VERSION "berumiya 990S labo"
CM_ "License: CC-BY 4.0";
CM_ "Repository : https://github.com/berumiya/CAN_DBC_6thGenMazda";
CM_ "Decoded and maintained by berumiya 990S labo";
CM_ "Source : reverse-engineered CAN traffic.";

NS_ :

BS_:
BU_: HS_SSU HS_CMU HS_BCMM HS_LVL HS_ABS HS_IC HS_RCM HS_EPAS HS_FSC2 HS_PCM HS_EVP HS_DCDC HS_MRCC HS_HUD_MZ HS_RHT HS_TCUAT OBD2 UNKNOWN_ECU
BO_ 145 HS_SSU: 8 HS_SSU
   SG_ MsgCounter_maybe : 31|8@0+ (1,0) [0|255] "" Vector__XXX
   SG_ HAZ_SW : 10|1@0+ (1,0) [0|1] "" Vector__XXX
   SG_ WIP_F_INT : 55|8@0+ (1,0) [0|1] "" Vector__XXX
   SG_ TURN_SW : 13|2@0+ (1,0) [0|1] "" Vector__XXX
   SG_ FOG_SW : 1|2@0+ (1,0) [0|1] "" Vector__XXX
   SG_ RearWiper : 19|2@0+ (1,0) [0|1] "" Vector__XXX
   SG_ Washer : 17|2@0+ (1,0) [0|1] "" Vector__XXX
   SG_ FrontWiper : 21|2@0+ (1,0) [0|1] "" Vector__XXX
   SG_ LIGHT : 7|6@0+ (1,0) [0|1] "" Vector__XXX

BO_ 70 HS_SSU: 8 HS_SSU

BO_ 80 HS_SSU: 8 HS_SSU
   SG_ iStop_EngineStopped_2 : 20|1@0+ (1,0) [0|1] "" Vector__XXX
   SG_ KeyState : 1|2@0+ (1,0) [0|1] "" Vector__XXX
   SG_ KeyStateInv : 58|3@0+ (1,0) [0|1] "" Vector__XXX
   SG_ StarterInterLockSW : 25|1@0+ (1,0) [0|1] "" Vector__XXX

BO_ 130 HS_SSU: 8 HS_SSU
   SG_ Steering_Wheel_Absolute_Angle : 23|16@0+ (0.05,-1600) [0|1] "deg" Vector__XXX
   SG_ SteeringRate_Abs_maybe : 44|12@1+ (0.5,0) [0|2047] "deg/s" Vector__XXX
   SG_ SteeringRate_Dir_maybe : 56|1@1+ (1,0) [0|1] "" Vector__XXX

BO_ 157 HS_SSU: 8 HS_SSU
   SG_ CRU_CON_SW1 : 7|10@0+ (1,0) [0|1] "" Vector__XXX
   SG_ CruiseMainSwitch_maybe : 13|1@0+ (1,0) [0|1] "" Vector__XXX

BO_ 628 HS_SSU: 8 HS_SSU
   SG_ INFO_SW : 61|2@0+ (1,0) [0|1] "" Vector__XXX
   SG_ Key_hold : 20|1@0+ (1,0) [0|1] "" Vector__XXX
   SG_ Key_notfound : 36|1@0+ (1,0) [0|1] "" Vector__XXX
   SG_ IC_Buzz : 7|8@0+ (1,0) [0|1] "" Vector__XXX
   SG_ Key_Batt : 39|1@0+ (1,0) [0|1] "" Vector__XXX
   SG_ Key_fob : 47|4@0+ (1,0) [0|1] "" Vector__XXX

BO_ 1154 HS_SSU: 8 HS_SSU

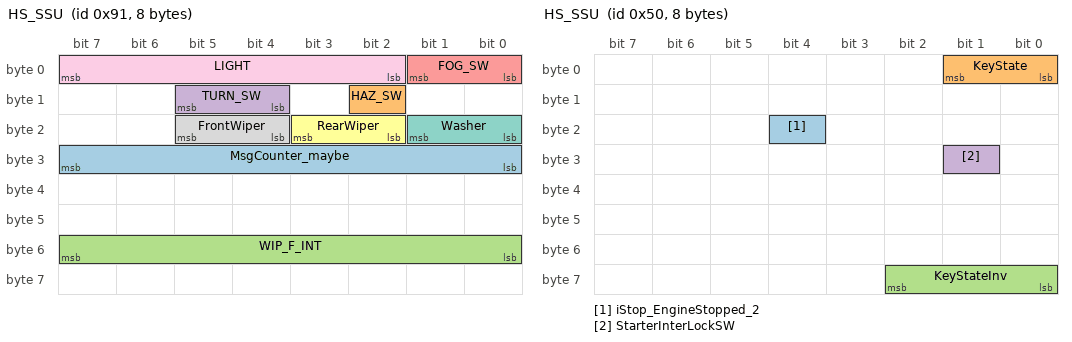
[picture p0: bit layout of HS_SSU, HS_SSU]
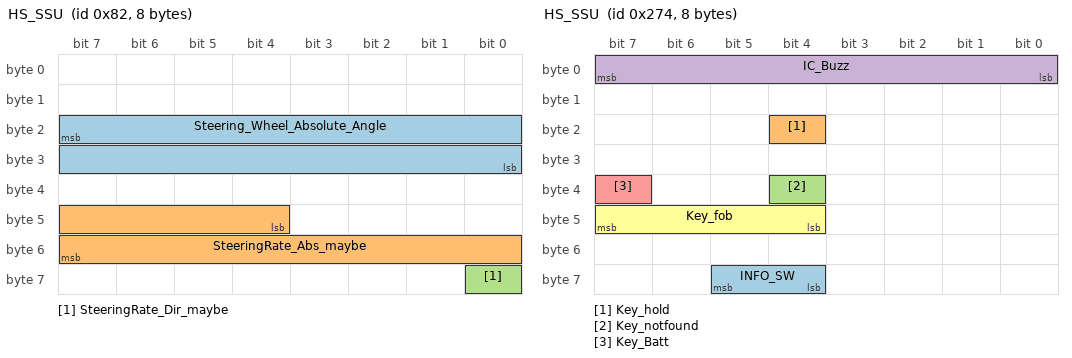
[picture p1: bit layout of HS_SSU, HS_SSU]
BO_ 1416 HS_SSU: 8 HS_SSU

BO_ 158 HS_IC: 8 HS_IC
   SG_ Fuel_Tank : 47|8@0+ (0.2,0) [0|1] "L" Vector__XXX
   SG_ Fuel_Related_2 : 55|8@0+ (1,0) [0|1] "" Vector__XXX
   SG_ DSC_OFF_Switch : 3|1@0+ (1,0) [0|1] "" Vector__XXX
   SG_ LDWS_ON_Switch : 8|1@0+ (1,0) [0|1] "" Vector__XXX
   SG_ BSM_RVM_ON_Switch : 9|1@0+ (1,0) [0|1] "" Vector__XXX
   SG_ iStop_OFF_Switch : 2|1@0+ (1,0) [0|1] "" Vector__XXX

BO_ 159 HS_IC: 8 HS_IC
   SG_ EngineRunning_2 : 16|1@0+ (1,0) [0|1] "" Vector__XXX
   SG_ PCONSW_Panel_Light_Control_Switch : 15|8@0+ (1,0) [0|1] "%" Vector__XXX
   SG_ DIM_CSW_Dimmer_Cancel_Switch : 47|1@0+ (1,0) [0|1] "" Vector__XXX
   SG_ Reverse_Flag_maybe : 7|1@0+ (1,0) [0|1] "" Vector__XXX
   SG_ ReverseGear_IC : 0|1@0+ (1,0) [0|1] "" Vector__XXX
   SG_ Parking_Brake : 4|1@0+ (1,0) [0|1] "" Vector__XXX

BO_ 606 HS_IC: 8 HS_IC
   SG_ VehicleSpeed : 7|10@0+ (1,0) [0|1] "" HS_HUD_MZ
   SG_ SpeedUnit : 13|1@0+ (1,0) [0|1] "" Vector__XXX
   SG_ StopVehicle : 28|1@0+ (1,0) [0|1] "" Vector__XXX
   SG_ DAA_Related : 63|4@0+ (1,0) [0|1] "" Vector__XXX

BO_ 607 HS_IC_PSM_MZ: 8 HS_IC

BO_ 1034 HS_IC_CentralConfig: 8 HS_IC
   SG_ C000_TOTAL_TIME m49152M : 23|32@0+ (0.1,1) [0|1] "sec" Vector__XXX
   SG_ C001_ODO m49153M : 23|32@0+ (1,0) [0|1] "km" Vector__XXX
   SG_ C100_VIN_1_6 m49408M : 23|48@0- (1,0) [0|1] "" Vector__XXX
   SG_ C101_VIN_7_12 m49409M : 23|48@0- (1,0) [0|1] "" Vector__XXX
   SG_ C102_VIN_13_17 m49410M : 23|40@0- (1,0) [0|1] "" Vector__XXX
   SG_ C103 m49411M : 23|48@0+ (1,0) [0|1] "" Vector__XXX
   SG_ C104 m49412M : 23|48@0+ (1,0) [0|1] "" Vector__XXX
   SG_ BF00_IG_ON_Timer m48896M : 39|16@0+ (1,0) [0|1] "sec" Vector__XXX
   SG_ BF01 m48897M : 23|48@0+ (1,0) [0|1] "" Vector__XXX
   SG_ BF02 m48898M : 23|48@0+ (1,0) [0|1] "" Vector__XXX
   SG_ BF03 m48899M : 23|48@0+ (1,0) [0|1] "" Vector__XXX
   SG_ BF04 m48900M : 23|48@0+ (1,0) [0|1] "" Vector__XXX
   SG_ BF05 m48901M : 23|48@0+ (1,0) [0|1] "" Vector__XXX
   SG_ BF06 m48902M : 23|48@0+ (1,0) [0|1] "" Vector__XXX
   SG_ BF07 m48903M : 23|48@0+ (1,0) [0|1] "" Vector__XXX
   SG_ BF08 m48904M : 23|48@0+ (1,0) [0|1] "" Vector__XXX
   SG_ BF09 m48905M : 23|48@0+ (1,0) [0|1] "" Vector__XXX
   SG_ BF0A m48906M : 23|48@0+ (1,0) [0|1] "" Vector__XXX
   SG_ BF0B m48907M : 23|48@0+ (1,0) [0|1] "" Vector__XXX
   SG_ BF0C m48908M : 23|48@0+ (1,0) [0|1] "" Vector__XXX
   SG_ BF0D m48909M : 23|48@0+ (1,0) [0|1] "" Vector__XXX
   SG_ BF0E m48910M : 23|48@0+ (1,0) [0|1] "" Vector__XXX
   SG_ BF0F m48911M : 23|48@0+ (1,0) [0|1] "" Vector__XXX
   SG_ BF10 m48912M : 23|48@0+ (1,0) [0|1] "" Vector__XXX
   SG_ BF11 m48913M : 23|48@0+ (1,0) [0|1] "" Vector__XXX
   SG_ BF12 m48914M : 23|48@0+ (1,0) [0|1] "" Vector__XXX
   SG_ BF13 m48915M : 23|48@0+ (1,0) [0|1] "" Vector__XXX
   SG_ BF14 m48916M : 23|48@0+ (1,0) [0|1] "" Vector__XXX
   SG_ BF15 m48917M : 23|48@0+ (1,0) [0|1] "" Vector__XXX
   SG_ BF16 m48918M : 23|48@0+ (1,0) [0|1] "" Vector__XXX
   SG_ BF17 m48919M : 23|48@0+ (1,0) [0|1] "" Vector__XXX
   SG_ BF18 m48920M : 23|48@0+ (1,0) [0|1] "" Vector__XXX
   SG_ BF19 m48921M : 23|48@0+ (1,0) [0|1] "" Vector__XXX
   SG_ BF1A m48922M : 23|48@0+ (1,0) [0|1] "" Vector__XXX
   SG_ BF1B m48923M : 23|48@0+ (1,0) [0|1] "" Vector__XXX
   SG_ BF1C m48924M : 23|48@0+ (1,0) [0|1] "" Vector__XXX
   SG_ BF1D m48925M : 23|48@0+ (1,0) [0|1] "" Vector__XXX
   SG_ BF1E m48926M : 23|48@0+ (1,0) [0|1] "" Vector__XXX
   SG_ BF1F m48927M : 23|48@0+ (1,0) [0|1] "" Vector__XXX
   SG_ BF20 m48928M : 23|48@0+ (1,0) [0|1] "" Vector__XXX
   SG_ BF21 m48929M : 23|48@0+ (1,0) [0|1] "" Vector__XXX
   SG_ Central_Config_Index M : 7|16@0+ (1,0) [0|1] "" Vector__XXX

BO_ 1078 HS_IC_EATC: 8 HS_IC

BO_ 1093 HS_IC_PSM_MZ: 8 HS_IC
   SG_ ReverseGear : 7|1@0+ (1,0) [0|1] "" Vector__XXX
   SG_ PSM_State_maybe : 23|8@0+ (1,0) [0|255] "" Vector__XXX

BO_ 1143 HS_IC: 8 HS_IC
   SG_ GearDisplay_related_maybe : 15|8@0+ (1,0) [0|255] "" Vector__XXX

BO_ 1147 HS_IC: 8 HS_IC
   SG_ BSM_Warning : 2|1@0+ (1,0) [0|1] "" Vector__XXX
   SG_ BSM_Right : 1|1@0+ (1,0) [0|1] "" Vector__XXX
   SG_ BSM_Left : 15|1@0+ (1,0) [0|1] "" Vector__XXX
   SG_ BSM_Status : 4|1@0+ (1,0) [0|1] "" Vector__XXX

BO_ 1166 HS_IC_PSM_MZ: 8 HS_IC

BO_ 1170 HS_IC: 8 HS_IC

BO_ 1173 HS_IC: 8 HS_IC

BO_ 1180 HS_IC: 8 HS_IC
   SG_ RoadIncline_maybe : 63|7@0+ (1,-32) [-32|95] "%" Vector__XXX

BO_ 1267 HS_IC: 8 HS_IC
   SG_ AvgFuelConsumption : 39|16@0+ (0.01,0) [0|655.35] "l/100km" Vector__XXX

BO_ 1271 HS_IC: 8 HS_IC
   SG_ ColdEngine_Indicator : 5|2@0+ (1,0) [0|3] "" Vector__XXX

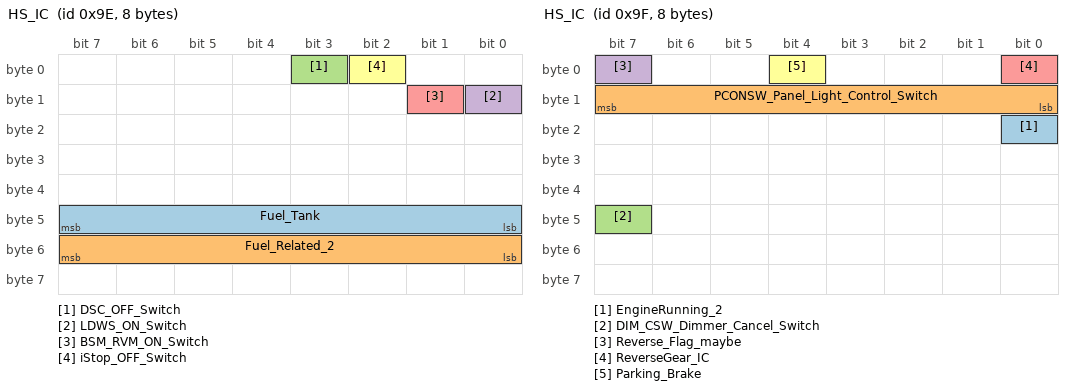
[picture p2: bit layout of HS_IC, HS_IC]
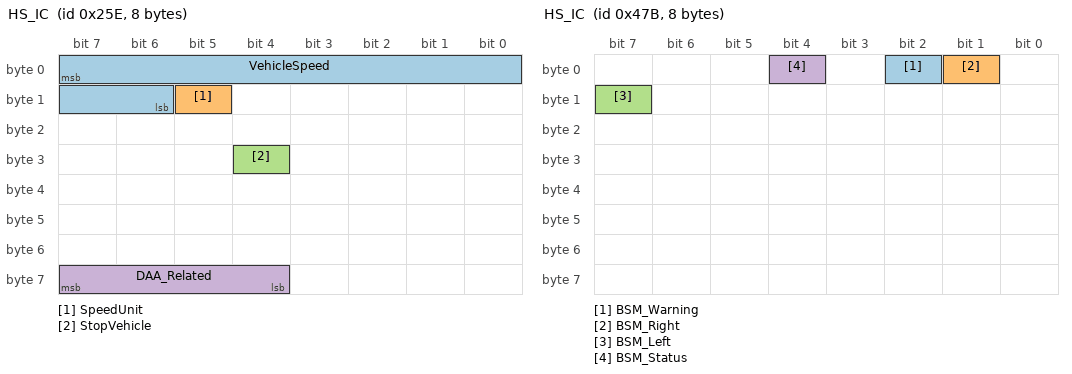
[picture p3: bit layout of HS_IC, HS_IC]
BO_ 1425 HS_IC: 8 HS_IC

BO_ 1776 HS_IC_NSWdiag: 8 HS_IC

BO_ 1778 HS_IC_NSWdiag: 8 HS_IC

BO_ 120 HS_ABS: 8 HS_ABS
   SG_ BrakePressure : 39|16@0- (0.0012709,33.5487) [0|45] "bar" Vector__XXX
   SG_ Longi_Acc_Corr : 7|16@0+ (0.000512295,-29.2787) [0|1] "G" Vector__XXX
   SG_ YawRate_related : 23|16@0- (0.0011,0) [-45|45] "deg/s" Vector__XXX

BO_ 121 HS_ABS: 8 HS_ABS
   SG_ MsgCounter_maybe : 55|8@0+ (1,0) [0|255] "" Vector__XXX
   SG_ Lateral_Acc_Corr_maybe : 7|16@0+ (0.000512295,-29.2787) [0|1] "" Vector__XXX
   SG_ YawRate_Corr : 31|16@0+ (0.133,-68.1) [-45|45] "deg/s" Vector__XXX

BO_ 529 HS_ABS: 8 HS_ABS
   SG_ ABS_Active : 42|1@0+ (1,0) [0|1] "" Vector__XXX
   SG_ TCS_Active_maybe : 40|1@0+ (1,0) [0|1] "" Vector__XXX
   SG_ HighDecel_maybe : 43|1@0+ (1,0) [0|1] "" Vector__XXX
   SG_ TCS_TorqueRequest_maybe : 23|16@0+ (1,-32768) [-32768|32767] "" Vector__XXX
   SG_ TCS_RequestActive_maybe : 53|1@0+ (1,0) [0|1] "" Vector__XXX

BO_ 533 HS_ABS: 8 HS_ABS
   SG_ WheelSpeed_1 : 7|16@0+ (0.01,-100) [0|1] "km/h" Vector__XXX
   SG_ WheelSpeed_2 : 23|16@0+ (0.01,-100) [0|1] "km/h" Vector__XXX
   SG_ WheelSpeed_3 : 39|16@0+ (0.01,-100) [0|1] "km/h" Vector__XXX
   SG_ WheelSpeed_4 : 55|16@0+ (0.01,-100) [0|1] "km/h" Vector__XXX

BO_ 535 HS_ABS: 8 HS_ABS
   SG_ VehicleSpeed_ABS_raw : 39|16@0+ (0.01,0) [0|655.35] "km/h" Vector__XXX

BO_ 542 HS_ABS: 8 HS_ABS
   SG_ MsgCounter_maybe : 55|8@0+ (1,0) [0|255] "" Vector__XXX

BO_ 736 HS_ABS: 8 HS_ABS

BO_ 1045 HS_ABS: 8 HS_ABS
   SG_ BrakeRelated_weak_maybe : 15|8@0+ (1,0) [0|255] "" Vector__XXX
   SG_ DSC_Status : 4|1@0+ (1,0) [0|1] "" Vector__XXX
   SG_ DSC_Indicator_maybe : 2|2@0+ (1,0) [0|3] "" Vector__XXX

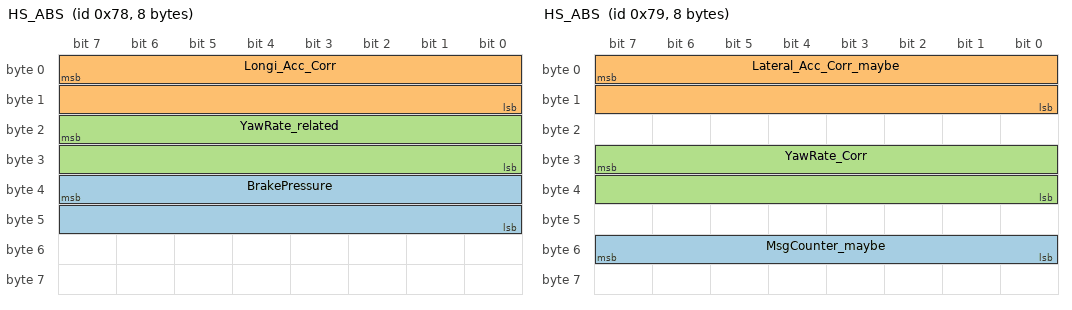
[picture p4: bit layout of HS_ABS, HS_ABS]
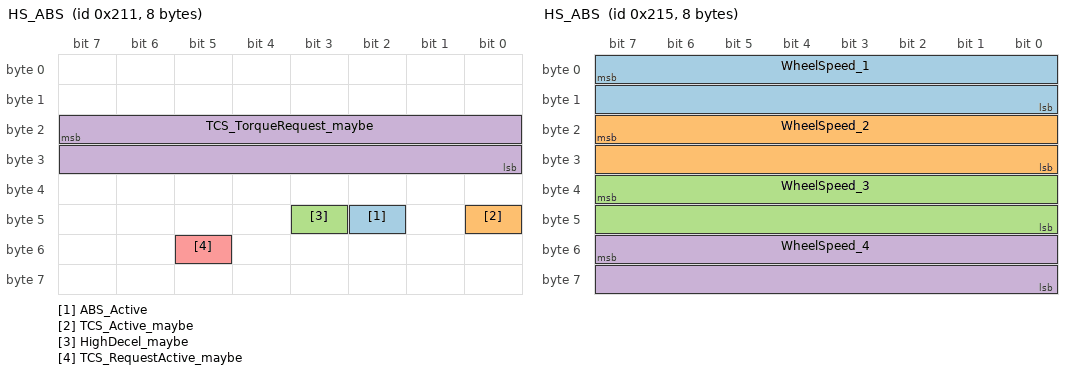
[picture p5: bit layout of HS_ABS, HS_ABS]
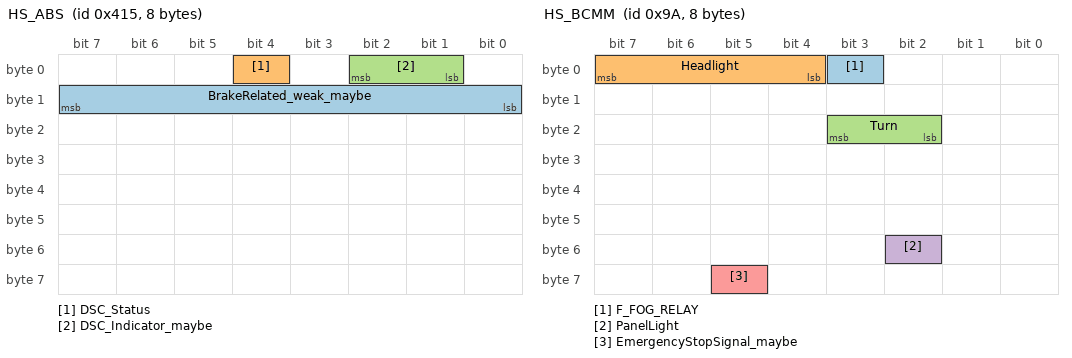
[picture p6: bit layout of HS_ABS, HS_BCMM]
BO_ 1430 HS_ABS: 8 HS_ABS

BO_ 154 HS_BCMM: 8 HS_BCMM
   SG_ F_FOG_RELAY : 3|1@0+ (1,0) [0|1] "" Vector__XXX
   SG_ Headlight : 7|4@0+ (1,0) [0|1] "" Vector__XXX
   SG_ Turn : 19|2@0+ (1,0) [0|1] "" Vector__XXX
   SG_ PanelLight : 50|1@0+ (1,0) [0|1] "" Vector__XXX
   SG_ EmergencyStopSignal_maybe : 61|1@0+ (1,0) [0|1] "" Vector__XXX

BO_ 155 HS_BCMM: 8 HS_BCMM

BO_ 1085 HS_BCMM: 8 HS_BCMM

BO_ 1086 HS_BCMM: 8 HS_BCMM
   SG_ ROOM_FUSE : 51|1@0+ (1,0) [0|1] "" Vector__XXX
   SG_ R_FOG_LAMP : 6|1@0+ (1,0) [0|1] "" Vector__XXX
   SG_ Trunk : 47|1@0+ (1,0) [0|1] "" Vector__XXX
   SG_ DoorRight : 37|1@0+ (1,0) [0|1] "" Vector__XXX
   SG_ DoorLeft : 36|1@0+ (1,0) [0|1] "" Vector__XXX
   SG_ AnyDoorOpen : 30|1@0+ (1,0) [0|1] "" Vector__XXX
   SG_ BrakeLamp : 53|1@0+ (1,0) [0|1] "" Vector__XXX

BO_ 1087 HS_BCMM: 8 HS_BCMM
   SG_ BCM_SupplyVoltage : 19|10@0+ (0.016,0) [0|16.37] "V" Vector__XXX
   SG_ Fuel_Related : 7|10@0+ (1,0) [0|1] "" Vector__XXX

BO_ 1114 HS_BCMM: 8 HS_BCMM
   SG_ BattSensor_Voltage_maybe : 45|13@0+ (0.002,-0.1) [0|16] "V" Vector__XXX
   SG_ BattSensor_Current_raw_maybe : 3|12@0+ (1,0) [0|4095] "" Vector__XXX
   SG_ BattSensor_Temp_maybe : 31|8@0+ (1,-40) [-40|215] "degC" Vector__XXX
   SG_ BattSensor_Byte4_maybe : 39|8@0+ (1,0) [0|255] "" Vector__XXX
   SG_ BattSensor_Byte7_maybe : 63|8@0+ (1,0) [0|255] "" Vector__XXX

BO_ 1115 HS_BCMM: 8 HS_BCMM

BO_ 1116 HS_BCMM: 8 HS_BCMM

BO_ 1163 HS_BCMM: 8 HS_BCMM

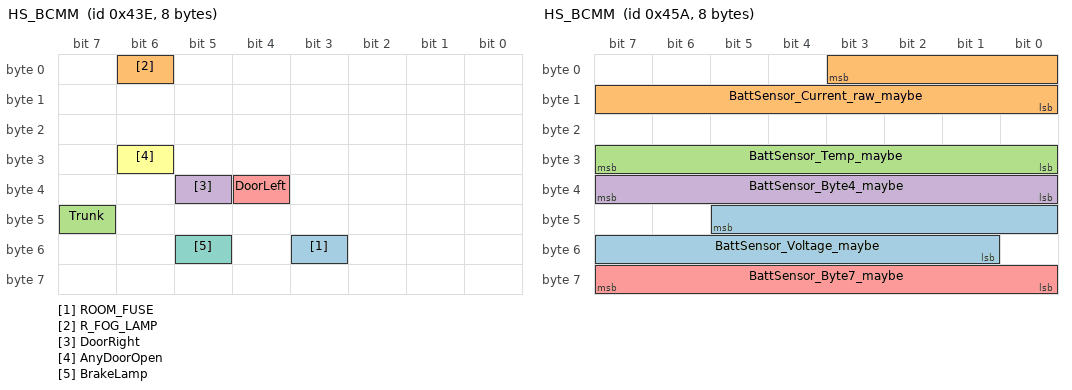
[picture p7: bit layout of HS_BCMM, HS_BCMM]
BO_ 1409 HS_BCMM: 8 HS_BCMM

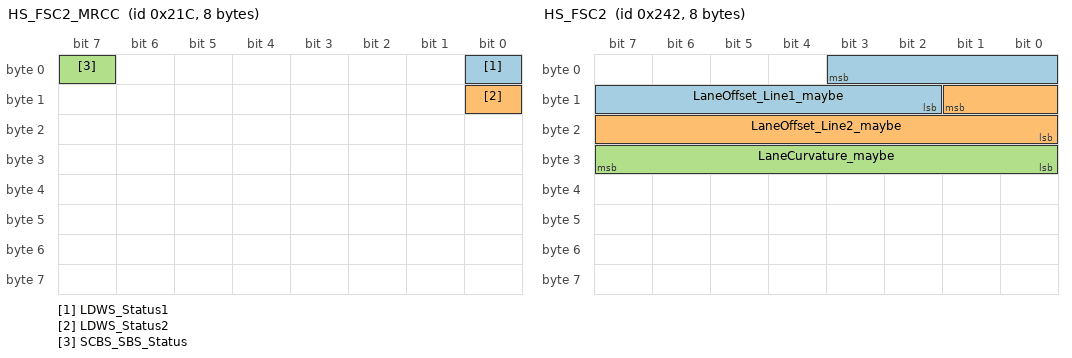
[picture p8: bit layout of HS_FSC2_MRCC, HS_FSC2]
BO_ 540 HS_FSC2_MRCC: 8 HS_FSC2
   SG_ LDWS_Status1 : 0|1@0+ (1,0) [0|1] "" Vector__XXX
   SG_ LDWS_Status2 : 8|1@0+ (1,0) [0|1] "" Vector__XXX
   SG_ SCBS_SBS_Status : 7|1@0+ (1,0) [0|1] "" Vector__XXX

BO_ 541 HS_FSC2: 8 HS_FSC2

BO_ 578 HS_FSC2: 8 HS_FSC2
   SG_ LaneOffset_Line1_maybe : 3|10@0+ (1,-686) [-686|337] "cm" Vector__XXX
   SG_ LaneOffset_Line2_maybe : 9|10@0+ (1,-686) [-686|337] "cm" Vector__XXX
   SG_ LaneCurvature_maybe : 31|8@0+ (0.3,-38.1) [-38.1|38.4] "1/km" Vector__XXX

BO_ 579 HS_FSC2: 8 HS_FSC2

BO_ 580 HS_FSC2: 8 HS_FSC2

BO_ 581 HS_FSC2: 8 HS_FSC2
   SG_ CAM581_Curvature2_raw_maybe : 39|8@0+ (1,0) [0|255] "" Vector__XXX
   SG_ CAM581_LineDiff_raw_maybe : 7|8@0+ (1,0) [0|255] "" Vector__XXX

BO_ 582 HS_FSC2: 8 HS_FSC2

BO_ 605 HS_FSC2: 8 HS_FSC2

BO_ 863 HS_FSC2: 8 HS_FSC2
   SG_ TSR_SpeedLimit : 4|7@0+ (1,0) [0|127] "km/h" Vector__XXX

BO_ 1088 HS_FSC2: 8 HS_FSC2

BO_ 1157 HS_FSC2: 8 HS_FSC2
   SG_ SCBS_SBS_Status : 28|2@0+ (1,0) [0|1] "" Vector__XXX

BO_ 1160 HS_FSC2: 8 HS_FSC2

BO_ 1061 HS_LVL: 8 HS_LVL

BO_ 64 HS_PCM: 8 HS_PCM

BO_ 253 HS_PCM: 8 HS_PCM
   SG_ EngineRunning_3 : 6|1@0+ (1,0) [0|1] "" Vector__XXX
   SG_ EngineRunning : 0|1@0+ (1,0) [0|1] "" Vector__XXX
   SG_ FuelCut : 41|1@0+ (1,0) [0|1] "" Vector__XXX
   SG_ MT_Gear_Recommend : 13|3@0+ (1,0) [0|1] "" Vector__XXX
   SG_ MT_Gear_Actual : 19|3@0+ (1,0) [0|1] "" Vector__XXX
   SG_ MAP_Manifold_absolute_pressure_sensor : 55|8@0+ (1,2) [10|115] "kPa" Vector__XXX
   SG_ CruiseActive_Inv : 61|1@0+ (1,0) [0|1] "" Vector__XXX

BO_ 254 HS_PCM: 8 HS_PCM
   SG_ MsgCounter_maybe : 55|8@0+ (1,0) [0|255] "" Vector__XXX
   SG_ SlowlyVarying_unclear : 63|8@0+ (1,0) [0|255] "" Vector__XXX

BO_ 357 HS_PCM: 8 HS_PCM
   SG_ Clutch_Related : 22|7@0+ (1,0) [0|1] "" Vector__XXX
   SG_ MT_Gear_Select : 36|2@0+ (1,0) [0|1] "" Vector__XXX
   SG_ CC_SetSpeed : 14|8@0+ (1,0) [0|1] "km/h" Vector__XXX
   SG_ CC_Mode_Related : 7|9@0+ (1,0) [0|1] "" Vector__XXX
   SG_ CC_Mode_Related2 : 31|8@0+ (1,0) [0|1] "" Vector__XXX
   SG_ MT_Gear_Position : 55|8@0+ (1,0) [0|255] "" Vector__XXX

BO_ 358 HS_PCM: 8 HS_PCM
   SG_ Clutch_Pedal_Position_related_2 : 7|8@0+ (1.25,0) [0|199] "" Vector__XXX
   SG_ BBP_Brake_Booster_Pressure_2 : 11|12@0+ (0.1,0) [0|1] "kPa" Vector__XXX
   SG_ BARO_Barometric_pressure : 35|12@0+ (0.1,-267) [0|1] "kPa" Vector__XXX

BO_ 304 HS_PCM: 8 HS_PCM
   SG_ iStop_Ready_maybe : 20|1@0+ (1,0) [0|1] "" Vector__XXX
   SG_ iStop_EngineStopped : 19|1@0+ (1,0) [0|1] "" Vector__XXX
   SG_ iStop_Stopping_B : 10|1@0+ (1,0) [0|1] "" Vector__XXX
   SG_ iStop_Stopping_A : 0|1@0+ (1,0) [0|1] "" Vector__XXX
   SG_ iStop_StopRequest : 30|1@0+ (1,0) [0|1] "" Vector__XXX
   SG_ EngineRPM_related_2 : 47|16@0+ (0.5,0) [0|8000] "rpm" Vector__XXX
   SG_ Clutch_Pedal_Position_raw : 63|8@0+ (1,0) [0|199] "" Vector__XXX

BO_ 359 HS_PCM: 8 HS_PCM
   SG_ iStop_StopRequest_PCM : 22|1@0+ (1,0) [0|1] "" Vector__XXX
   SG_ APP_Accelerator_Pedal_Position : 7|10@0+ (0.1,0) [0|1] "%" Vector__XXX
   SG_ ActualEnginePercentTorque : 39|8@0+ (3.1028,-183.019) [-183.019|608.195] "%" Vector__XXX
   SG_ BrakeSwitch_PCM : 19|1@0+ (1,0) [0|1] "" Vector__XXX
   SG_ BrakeSwitch_PCM_Inv : 18|1@0+ (1,0) [0|1] "" Vector__XXX
   SG_ BrakeSwitch_PCM_2 : 16|1@0+ (1,0) [0|1] "" Vector__XXX

BO_ 512 HS_PCM: 8 HS_PCM
   SG_ PCM_TorqueLoss_raw_maybe : 23|16@0+ (1,-32768) [-32768|32767] "" Vector__XXX
   SG_ EngineLoad_related_maybe : 7|16@0+ (1,0) [0|65535] "" Vector__XXX
   SG_ EngineTorque_related_maybe : 39|16@0+ (1,0) [0|65535] "" Vector__XXX

BO_ 514 HS_PCM: 8 HS_PCM
   SG_ EngineRPM : 7|16@0+ (0.25,0) [0|1] "rpm" Vector__XXX
   SG_ VehicleSpeed : 23|16@0+ (0.01,0) [0|1] "km/h" Vector__XXX
   SG_ APP_Accelerator_Pedal_Position : 39|16@0+ (0.0015625,0) [0|1] "%" Vector__XXX

BO_ 522 HS_PCM_w_i_ELOOP: 8 HS_PCM
   SG_ EngineState_raw_maybe : 7|6@0+ (1,0) [0|63] "" Vector__XXX
   SG_ PCM_20A_Ramp_raw_maybe : 1|8@0+ (1,0) [0|255] "" Vector__XXX
   SG_ FuelNotCut_maybe : 39|1@0+ (1,0) [0|1] "" Vector__XXX

BO_ 543 HS_PCM: 8 HS_PCM

BO_ 1056 HS_PCM: 8 HS_PCM
   SG_ FuelConsumption_Counter : 23|8@0+ (1,0) [0|255] "" Vector__XXX
   SG_ CoolantTemp : 7|8@0+ (1,-40) [0|1] "degC" Vector__XXX
   SG_ AmbientTemp : 63|8@0+ (0.25,0) [0|63.75] "degC" Vector__XXX
   SG_ Travel_distance_related : 15|8@0+ (0.1992,0) [0|50.8] "m" Vector__XXX

BO_ 1067 HS_PCM: 8 HS_PCM
   SG_ EngineRPM_related_3_maybe : 15|16@0+ (1,0) [0|1] "" Vector__XXX

BO_ 1233 HS_PCM: 8 HS_PCM

BO_ 1236 HS_PCM: 8 HS_PCM

BO_ 1237 HS_PCM: 8 HS_PCM

BO_ 1238 HS_PCM: 8 HS_PCM

BO_ 1239 HS_PCM: 8 HS_PCM

BO_ 1241 HS_PCM: 8 HS_PCM

BO_ 1242 HS_PCM: 8 HS_PCM

BO_ 1244 HS_PCM: 8 HS_PCM

BO_ 1264 HS_PCM: 8 HS_PCM

BO_ 1274 HS_PCM: 8 HS_PCM
   SG_ IAT_Sensor_No1 : 39|8@0+ (1,-40) [-40|160] "degC" Vector__XXX

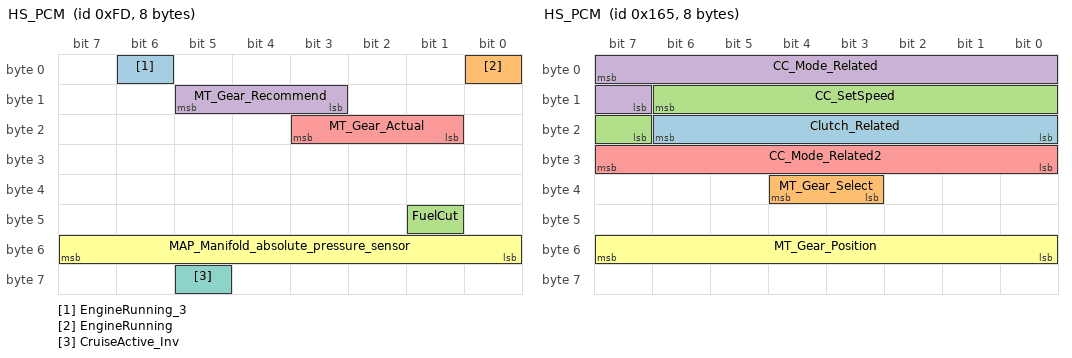
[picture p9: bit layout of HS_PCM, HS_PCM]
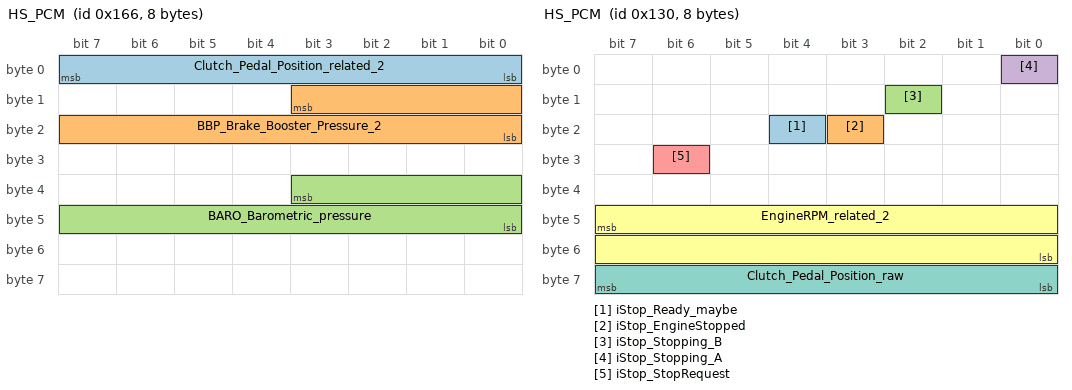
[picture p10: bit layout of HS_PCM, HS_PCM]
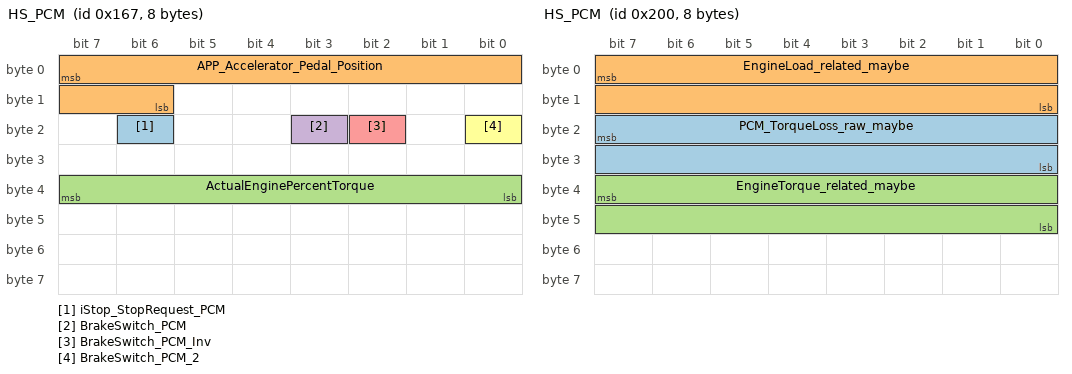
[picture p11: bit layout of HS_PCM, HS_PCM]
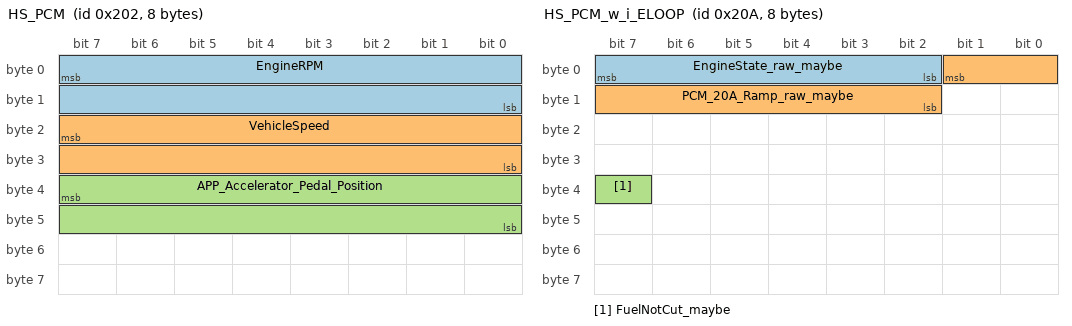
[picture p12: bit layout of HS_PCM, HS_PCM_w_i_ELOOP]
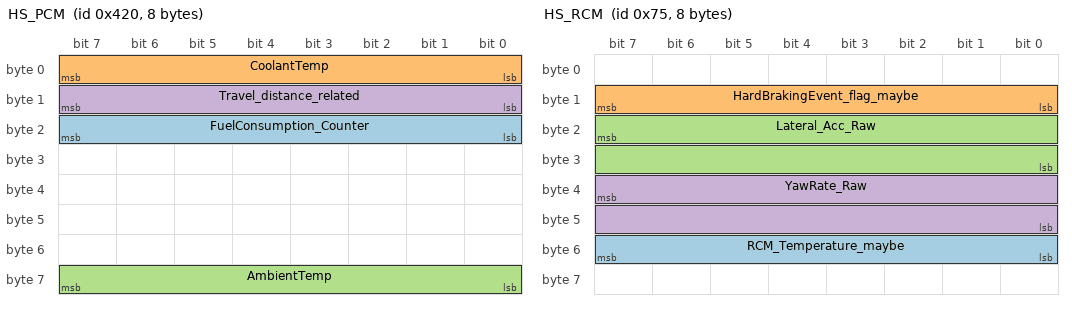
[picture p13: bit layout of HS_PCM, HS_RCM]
BO_ 1278 HS_PCM: 8 HS_PCM
   SG_ IgnitionTick_related : 2|11@0+ (1,0) [0|2047] "" Vector__XXX

BO_ 117 HS_RCM: 8 HS_RCM
   SG_ RCM_Temperature_maybe : 55|8@0+ (1,-103) [-103|152] "degC" Vector__XXX
   SG_ HardBrakingEvent_flag_maybe : 15|8@0+ (1,0) [0|255] "" Vector__XXX
   SG_ Lateral_Acc_Raw : 23|16@0+ (0.001,-2) [0|1] "G" Vector__XXX
   SG_ YawRate_Raw : 39|16@0+ (0.01,-180) [0|1] "deg/s" Vector__XXX

BO_ 118 HS_RCM: 8 HS_RCM
   SG_ HardBrakingEvent_flag_maybe : 15|8@0+ (1,0) [0|255] "" Vector__XXX
   SG_ Longitudinal_Acc_Raw : 23|16@0+ (0.001,-2) [0|1] "G" Vector__XXX

BO_ 832 HS_RCM: 8 HS_RCM
   SG_ PassengerSeatbelt_Buckled : 26|1@1+ (1,0) [0|1] "" Vector__XXX
   SG_ PassengerSeatOccupied_maybe : 16|1@1+ (1,0) [0|1] "" Vector__XXX
   SG_ DriverSeatbelt_Buckled : 27|1@1+ (1,0) [0|1] "" Vector__XXX
   SG_ PassengerSeatEmpty_maybe : 28|1@1+ (1,0) [0|1] "" Vector__XXX
   SG_ PassengerSeatPending_maybe : 30|1@1+ (1,0) [0|1] "" Vector__XXX

BO_ 834 HS_RCM: 8 HS_RCM

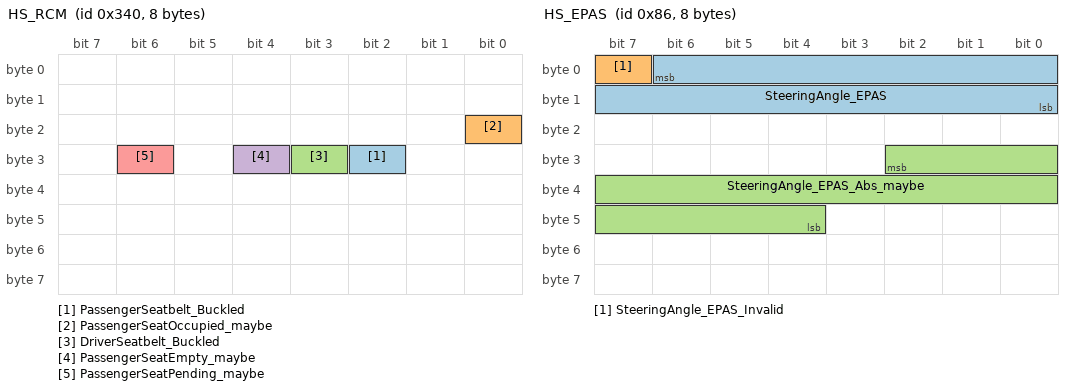
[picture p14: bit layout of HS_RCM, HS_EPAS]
BO_ 1108 HS_RCM: 8 HS_RCM

BO_ 134 HS_EPAS: 8 HS_EPAS
   SG_ SteeringAngle_EPAS : 6|15@0+ (0.1,-1600) [-1600|1676.7] "deg" Vector__XXX
   SG_ SteeringAngle_EPAS_Invalid : 7|1@0+ (1,0) [0|1] "" Vector__XXX
   SG_ SteeringAngle_EPAS_Abs_maybe : 26|15@0+ (0.1,-1600) [-1600|1676.7] "deg" Vector__XXX

BO_ 284 HS_EPAS: 8 HS_EPAS

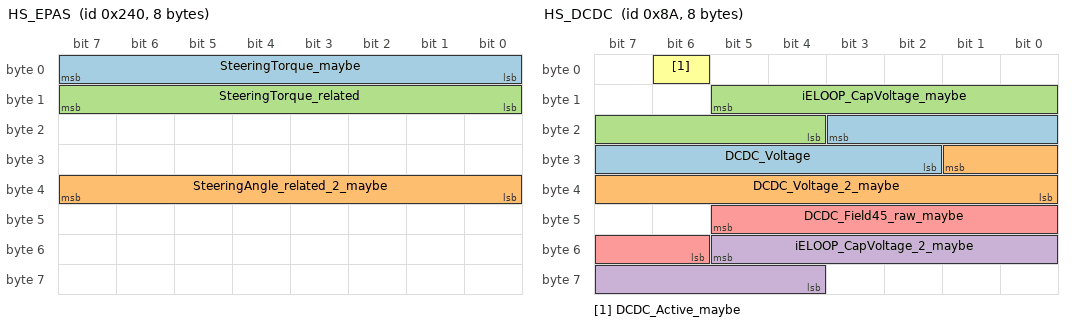
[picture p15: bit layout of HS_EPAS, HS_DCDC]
BO_ 576 HS_EPAS: 8 HS_EPAS
   SG_ SteeringTorque_maybe : 7|8@0+ (1,-127) [-127|128] "" Vector__XXX
   SG_ SteeringAngle_related_2_maybe : 39|8@0+ (1,0) [0|255] "" Vector__XXX
   SG_ SteeringTorque_related : 15|8@0+ (1,0) [0|1] "" Vector__XXX

BO_ 138 HS_DCDC: 8 HS_DCDC
   SG_ DCDC_Voltage : 19|10@0+ (0.02,0) [0|20.46] "V" Vector__XXX
   SG_ DCDC_Voltage_2_maybe : 25|10@0+ (0.02,0) [0|20.46] "V" Vector__XXX
   SG_ iELOOP_CapVoltage_maybe : 13|10@0+ (0.04,0) [0|40.92] "V" Vector__XXX
   SG_ iELOOP_CapVoltage_2_maybe : 53|10@0+ (0.04,0) [0|40.92] "V" Vector__XXX
   SG_ DCDC_Field45_raw_maybe : 45|8@0+ (1,0) [0|255] "" Vector__XXX
   SG_ DCDC_Active_maybe : 6|1@0+ (1,0) [0|1] "" Vector__XXX

BO_ 1243 HS_DCDC: 8 HS_DCDC
   SG_ DCDC_State_maybe : 31|8@0+ (1,0) [0|255] "" Vector__XXX
   SG_ DCDC_RegenFlag_maybe : 4|1@0+ (1,0) [0|1] "" Vector__XXX
   SG_ DCDC_RegenLevel_maybe : 7|3@0+ (1,0) [0|7] "" Vector__XXX

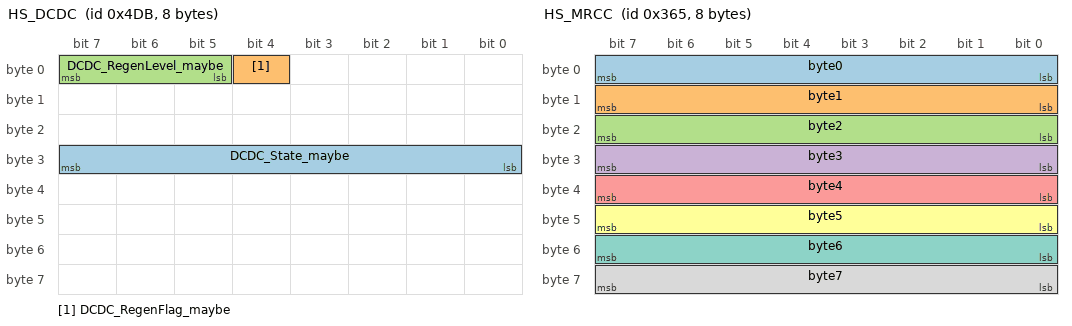
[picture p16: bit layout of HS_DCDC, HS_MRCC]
BO_ 1247 HS_DCDC: 8 HS_DCDC

BO_ 805 HS_EVP: 8 HS_EVP
   SG_ MsgCounter_maybe : 55|8@0+ (1,0) [0|255] "" Vector__XXX
   SG_ VS1_Vaccum_Sensor_1 : 7|12@0+ (0.1,0) [0|1] "kPa" Vector__XXX

BO_ 976 HS_CMU: 8 HS_CMU

BO_ 977 HS_CMU_MMmonth: 8 HS_CMU
   SG_ Date : 49|7@0+ (1,0) [0|1] "" Vector__XXX
   SG_ DistanceToService_related : 47|14@0+ (1,0) [0|16383] "km" Vector__XXX

BO_ 978 HS_CMU: 8 HS_CMU

BO_ 1171 HS_CMU: 8 HS_CMU

BO_ 1266 HS_CMU: 8 HS_CMU
   SG_ HUD_Height : 27|12@0+ (1,0) [0|1] "" Vector__XXX
   SG_ HUD_Height_Moving : 28|1@0+ (1,0) [0|1] "" Vector__XXX

BO_ 1272 HS_CMU: 8 HS_CMU

BO_ 1479 HS_CMU: 8 HS_CMU

BO_ 539 HS_MRCC: 8 HS_MRCC

BO_ 865 HS_MRCC: 8 HS_MRCC

BO_ 866 HS_MRCC: 8 HS_MRCC

BO_ 867 HS_MRCC: 8 HS_MRCC

BO_ 868 HS_MRCC: 8 HS_MRCC

BO_ 869 HS_MRCC: 8 HS_MRCC
   SG_ byte0 : 7|8@0+ (1,0) [0|1] "" Vector__XXX
   SG_ byte1 : 15|8@0+ (1,0) [0|1] "" Vector__XXX
   SG_ byte2 : 23|8@0+ (1,0) [0|1] "" Vector__XXX
   SG_ byte3 : 31|8@0+ (1,0) [0|1] "" Vector__XXX
   SG_ byte4 : 39|8@0+ (1,0) [0|1] "" Vector__XXX
   SG_ byte5 : 47|8@0+ (1,0) [0|1] "" Vector__XXX
   SG_ byte6 : 55|8@0+ (1,0) [0|1] "" Vector__XXX
   SG_ byte7 : 63|8@0+ (1,0) [0|1] "" Vector__XXX

BO_ 870 HS_MRCC: 8 HS_MRCC

BO_ 1177 HS_MRCC: 8 HS_MRCC

BO_ 1183 HS_HUD_MZ: 8 HS_HUD_MZ

BO_ 1269 HS_HUD_MZ: 8 HS_HUD_MZ

BO_ 1435 HS_HUD_MZ: 8 HS_HUD_MZ

BO_ 1138 HS_RHT_Maybe: 8 HS_RHT
   SG_ RoofGraphicStatus : 23|4@0+ (1,0) [0|1] "" Vector__XXX

BO_ 2016 OBD2_PCM: 8 OBD2

BO_ 2024 OBD2_PCM: 8 OBD2

BO_ 1988 OBD2_BSM: 8 OBD2

BO_ 1996 OBD2_BSM: 8 OBD2

BO_ 1975 OBD2_RBCM_ESU: 8 OBD2

BO_ 1983 OBD2_RBCM_ESU: 8 OBD2

BO_ 1970 OBD2_HUD_MZ: 8 OBD2

BO_ 1978 OBD2_HUD_MZ: 8 OBD2

BO_ 1907 OBD2_EVP: 8 OBD2

BO_ 1915 OBD2_EVP: 8 OBD2

BO_ 1892 OBD2_MRCC: 8 OBD2

BO_ 1900 OBD2_MRCC: 8 OBD2

BO_ 1888 OBD2_ABS: 8 OBD2

BO_ 1896 OBD2_ABS: 8 OBD2

BO_ 1847 OBD2_RCM: 8 OBD2

BO_ 1841 OBD2_SSU: 8 OBD2

BO_ 1849 OBD2_SSU: 8 OBD2

BO_ 1846 OBD2_PSM_MZ: 8 OBD2

BO_ 1854 OBD2_PSM_MZ: 8 OBD2

BO_ 1844 OBD2_AFS_ALM: 8 OBD2

BO_ 1852 OBD2_AFS_ALM: 8 OBD2

BO_ 1843 OBD2_EATC: 8 OBD2

BO_ 1851 OBD2_EATC: 8 OBD2

BO_ 1840 OBD2_EPAS: 8 OBD2

BO_ 1848 OBD2_EPAS: 8 OBD2

BO_ 1830 OBD2_FBCM_BCMM: 8 OBD2

BO_ 1838 OBD2_FBCM_BCMM: 8 OBD2

BO_ 1824 OBD2_IC: 8 OBD2

BO_ 1832 OBD2_IC: 8 OBD2

BO_ 1798 OBD2_FSC: 8 OBD2

BO_ 1806 OBD2_FSC: 8 OBD2

BO_ 2017 OBD2_TCM: 8 OBD2

BO_ 2025 OBD2_TCM: 8 OBD2

BO_ 1993 OBD2_360VMC: 8 OBD2

BO_ 1080 UNKNOWN_ECU: 8 Vector__XXX
   SG_ ASCII_string_maybe : 7|64@0+ (1,0) [0|1] "" Vector__XXX

BO_ 836 UNKNOWN_ECU: 8 Vector__XXX
   SG_ Flag_byte0_maybe : 7|8@0+ (1,0) [0|1] "" Vector__XXX
   SG_ Counter_byte6_maybe : 55|8@0+ (1,0) [0|1] "" Vector__XXX
   SG_ SlowVarying_byte7_maybe : 63|8@0+ (1,0) [0|1] "" Vector__XXX

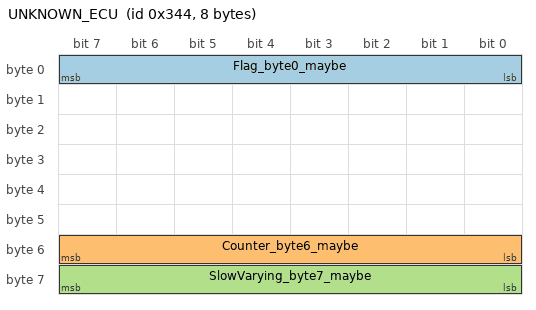
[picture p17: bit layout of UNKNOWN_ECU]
BO_ 1169 UNKNOWN_ECU: 8 Vector__XXX

BO_ 1832 HS_IC_TPMS_Response: 8 HS_IC
   SG_ TPMS_DID M : 23|16@0+ (1,0) [0|1] "" Vector__XXX
   SG_ Tire1_Pressure m10757M : 39|8@0+ (0.01373,0) [0|3.5] "bar" Vector__XXX
   SG_ Tire2_Pressure m10758M : 39|8@0+ (0.01373,0) [0|3.5] "bar" Vector__XXX
   SG_ Tire3_Pressure m10759M : 39|8@0+ (0.01373,0) [0|3.5] "bar" Vector__XXX
   SG_ Tire4_Pressure m10760M : 39|8@0+ (0.01373,0) [0|3.5] "bar" Vector__XXX
   SG_ Tire1_Temp_maybe m10762M : 39|8@0+ (1,-50) [-20|180] "C" Vector__XXX
   SG_ Tire2_Temp_maybe m10763M : 39|8@0+ (1,-50) [-20|180] "C" Vector__XXX
   SG_ Tire3_Temp_maybe m10764M : 39|8@0+ (1,-50) [-20|180] "C" Vector__XXX
   SG_ Tire4_Temp_maybe m10765M : 39|8@0+ (1,-50) [-20|180] "C" Vector__XXX

SG_MUL_VAL_ 1832 Tire1_Pressure TPMS_DID 10757-10757;
SG_MUL_VAL_ 1832 Tire2_Pressure TPMS_DID 10758-10758;
SG_MUL_VAL_ 1832 Tire3_Pressure TPMS_DID 10759-10759;
SG_MUL_VAL_ 1832 Tire4_Pressure TPMS_DID 10760-10760;
SG_MUL_VAL_ 1832 Tire1_Temp_maybe TPMS_DID 10762-10762;
SG_MUL_VAL_ 1832 Tire2_Temp_maybe TPMS_DID 10763-10763;
SG_MUL_VAL_ 1832 Tire3_Temp_maybe TPMS_DID 10764-10764;
SG_MUL_VAL_ 1832 Tire4_Temp_maybe TPMS_DID 10765-10765;

CM_ BO_ 1832 "Eigene Ergaenzung (2026-09-13), BESTAETIGT per Nutzer-OBD-Test + Cross-Check gegen candump-2026-09-12_211833.log (Y-Splitter-Log): dies ist KEINE periodische Broadcast-Botschaft, sondern die Antwort auf einen aktiven UDS-Request (Mode 0x22 ReadDataByIdentifier) an Header 0x720 (Kombiinstrument), siehe scripts/tpms_poller.py. Byte0=ISO-TP-PCI (hier immer 0x04, nicht als Signal modelliert), Byte1=SID 0x62 (ebenfalls nicht modelliert), TPMS_DID=Byte2-3=die angefragte PID. WICHTIG fuers Verstaendnis: entgegen einem Forenbericht (mx5-nd-forum.de), der Header 0x720 als NUR-MS-CAN beschreibt, ist diese Antwort nachweislich auch auf HS-CAN (can0, unsere einzige Verkabelung) sichtbar - im Y-Splitter-Log erscheinen 720#032... (Request) und 728#046... (Antwort) im exakt selben Zeitfenster, in dem die parallel per OBD-Fusion geloggten WU1-4_P_TPM_IC-Kanaele dieselben Werte zeigen (byte-genauer Abgleich, siehe Session). Response-ID 0x728 (Request+8) damit ebenfalls bestaetigt, vorher nur vermutet. Nur Druck-PIDs (2A05-2A08) live bestaetigt; Temperatur-PIDs (2A0A-2A0D) sind vom selben Nutzer per OBD live getestet worden (siehe Konversation), aber in KEINEM eigenen candump-Log bisher tatsaechlich als CAN-Frame beobachtet - bleiben _maybe.";
CM_ SG_ 1832 Tire3_Pressure "Rad-Zuordnung BESTAETIGT (2026-09-13): Nutzer meldete beim Y-Splitter-Log reale Reifendruecke 'hinten rechts=1.9 bar, hinten links=1.7 bar' (gerundet). Dekodierter Wert hier: 1.661 bar (WU3/Tire3, DID 0x2A07) - passt zu 'hinten links' (1.7 gerundet). Damit: Tire3 = Hinten Links (RL).";
CM_ SG_ 1832 Tire4_Pressure "Rad-Zuordnung BESTAETIGT (2026-09-13): siehe CM_ SG_ 1832 Tire3_Pressure. Dekodierter Wert hier: 1.922 bar (WU4/Tire4, DID 0x2A08) - passt zu 'hinten rechts=1.9 bar'. Damit: Tire4 = Hinten Rechts (RR).";
CM_ SG_ 1832 Tire1_Pressure "Rad-Zuordnung VERMUTUNG, NICHT bestaetigt (2026-09-13): Tire3=RL und Tire4=RR (siehe dortige Kommentare) passen zum ueblichen Nummerierungsschema Vorne-Links/Vorne-Rechts/Hinten-Links/Hinten-Rechts (1-2-3-4). Dekodierter Wert hier 1.799 bar, Tire2 1.757 bar - beide vermutlich Vorderachse, Reihenfolge (welches Vorne-Links vs. Vorne-Rechts ist) noch NICHT durch einen gezielten Test bestaetigt (z.B. gezieltes Ablassen von Luft an einem einzelnen Vorderrad). BESTAETIGT 2026-09-26: Tire1 = vorne links. Nutzer hat vorne rechts mit etwas weniger Druck gefuellt; die auf 20 C normierte Differenz Tire1-Tire2 lag vom 14. bis 19.09. taeglich bei 0,024-0,029 bar und am 26.09. bei 0,085 bar (69 Abfragen).";
CM_ SG_ 1832 Tire2_Pressure "BESTAETIGT 2026-09-26: Tire2 = vorne rechts (Herleitung siehe Tire1_Pressure).";

CM_ SG_ 130 Steering_Wheel_Absolute_Angle "FORScan_STR_AB_ANG";
CM_ SG_ 1034 C100_VIN_1_6 "Eigene Reverse-Engineering-Korrektur (2026-09-12), TIPPFEHLER-FIX: Original war 'm49408M : 23|48@4-' - '4' ist als Byte-Order-Ziffer im DBC-Format ungueltig (nur 0=Motorola/1=Intel erlaubt). cantools interpretiert jeden Nicht-Null-Wert stillschweigend als Little-Endian und baut dafuer ein eigenes Packformat, das mit den anderen 48-Bit-Feldern dieser gemultiplexten Botschaft (C103/C104/BF00-BF21, alle korrekt '23|48@0+') kollidiert -> 'ValueError: Short data' fuer jeden Frame mit diesem Multiplexer-Wert. Korrigiert auf '23|48@0-' (Motorola/big-endian, Vorzeichen-Flag '-' unveraendert uebernommen, passt zum gleichen Bitmuster 23|48/23|40 wie alle Geschwister-Felder in dieser Botschaft). Betrifft auch C101_VIN_7_12 und C102_VIN_13_17 (gleicher Tippfehler, gleicher Fix). Verifiziert gegen beide verfuegbaren Logs (candump-2026-09-12_120952.log + candump-2026-09-11_180456.log): alle 5901 Frames von 0x40A dekodieren jetzt fehlerfrei (vorher 316 Fehler durch genau diese drei Signale). Die drei Rohwerte ergeben durchgehend (>99% der jeweiligen Frames) als grosse-endian-Bytes interpretiert die ASCII-Zeichenfolge 'JMZND6' + 'E76004' + '12218' = 'JMZND6E7600412218' (17 Zeichen, exakt VIN-Laenge) - starkes Indiz, dass Position/Byte-Order jetzt korrekt sind, aber nicht gegen eine unabhaengige Fahrzeugschein-VIN gegengeprueft.";
CM_ SG_ 1034 C001_ODO "BESTAETIGT (2026-09-12): decodiert in candump-2026-09-12_120952.log durchgehend (219 Frames) zu 169756 km - deckt sich EXAKT mit dem am Kombiinstrument abgelesenen Gesamtkilometerstand. Im aelteren candump-2026-09-11_180456.log (77 Frames) 169749 km, 7km weniger, konsistent mit einer Fahrt am Vortag. Skalierung 1:1 km, keine Anpassung noetig, kein '_maybe' mehr noetig. Zum Vergleich: das damalige 'Mileage' bei 0x977 lieferte nur Muellwerte, war NICHT der Gesamtkilometerstand - 2026-09-21 aufgeloest, siehe CM_ SG_ 977 DistanceToService_related (dasselbe Byte-Umfeld traegt den ECHTEN, ODO-abgeleiteten Restkilometer-bis-Service-Zaehler).";
CM_ SG_ 977 DistanceToService_related "GEFUNDEN+BESTAETIGT (2026-09-21, Suche nach einem Datums-/Uhrzeitkanal fuer das No-RTC-Problem): kein Kalenderdatum, sondern ein Restkilometer-bis-naechster-Service-Zaehler. can_bitsearch.py gegen C001_ODO (0x40A) fand zunaechst ein 16-Bit-Feld (Startbit 47|16@0+) mit R²=1,0000; Ganz-Log-Regression ueber ALLE 34 verfuegbaren Logs (85.175 Punkte, ODO-Bereich 169749-170327km, 578km Spanne) bestaetigte raw16 = -4,0·ODO_km + 695053,45 (R²=1,000000 auf 6 Nachkommastellen). Die 16-Bit-Variante ueberlappte sich jedoch in Bit 54-55 mit dem bestehenden 'Date'-Signal (49|7@0+) und brachte cantools' decode() fuer die GESAMTE Botschaft zum Absturz ('unpacking failed', reproduzierbar mit allen 3 Signalen gleichzeitig) - deshalb auf 14 Bit (47|14@0+, Bits 40-53) verkuerzt, was die niederwertigsten 2 Bit (0,25km-Aufloesung) kostet, aber ueberlappungsfrei zu 'Date' ist. Erneute Ganz-Log-Regression mit dieser Breite: raw14 = -1,0·ODO_km + 173763,11 (R²=1,000000) - Skala und Nullstelle runden sauber auf 'raw14 = 173764 - ODO_km', also DIREKT die verbleibenden km bis zum naechsten Service (Skala 1, Offset 0 hier entsprechend eingetragen). Das urspruengliche Community-DBC-Signal 'Mileage' (39|22@0+, komplett andere Botschaft ueberlappend, dokumentiert als Muellwerte in CM_ SG_ 1034 C001_ODO) ist damit endgueltig widerlegt und ENTFERNT (nicht nur veraltet) - es kollidierte ausserdem mit diesem echten Feld und war der eigentliche Grund fuer den decode-Absturz. Siehe docs/logs/can-bus-status.md, Abschnitt 'Suche nach einem Datum/Uhrzeit-Kanal fuer das No-RTC-Problem'. UNABHAENGIG ZWEITBESTAETIGT (siehe CM_ BO_ 977): eine parallele Momentanverbrauch-Session fand dieselbe Bitlage/Steigung ueber einen komplett anderen Weg (Distanz-Sprung-Detektor statt Regression gegen C001_ODO). | DRITTE, UNABHAENGIGE BESTAETIGUNG (Offline-Ausbeute 2026-09-26, zunaechst als Service_DistanceRemaining_maybe gefunden, beim Merge vereinheitlicht): Eigene Reverse-Engineering-Ergaenzung (2026-09-26). 0x3D1 (HS_CMU) Byte5 + Byte6 Bit7..2 (14 Bit): zaehlt waehrend der Fahrt um 1 je ~1,05 km herunter (513 Schritte auf 538,8 km integrierter VehicleSpeed ueber alle Logs = 0,952/km; VehicleSpeed liegt vermutlich ~5 % ueber der Tachostrecke). Ueber alle 29 Logs lueckenlos stetig (Endwert eines Logs = Startwert des naechsten), einzige Luecke 41 km zwischen 16.09. und 17.09. (Fahrten ohne Logger). Verlauf 4008 km (12.09.) -> 3437 km (19.09.). Deutung: Restdistanz bis zur naechsten Wartung (Oelwechsel-/Service-Intervall). Das fruehere Community-Signal 'Mileage' (39|22) umfasste diese 14 Bit plus Byte4 (dessen Inhalt wechselt unabhaengig) und lieferte deshalb nur Muellwerte - ersetzt. Das Signal 'Date' (49|7) derselben Botschaft ist in allen Logs 0 bzw. sinnlos. Fahrzeugtest: Wartungsanzeige im MZD-Menue (Einstellungen > Fahrzeug > Wartung) ablesen und vergleichen.";
CM_ SG_ 977 Date "NACHTRAG (2026-09-21): der beobachtete seltene Wertwechsel (33->32, genau einmal in 9 Tagen/34 Logs, NICHT an einer Kalendertagesgrenze, siehe docs/logs/can-bus-status.md) spricht GEGEN ein echtes Kalenderdatum - vermutlich reiner Zufall oder ein weiteres falsch platziertes Community-DBC-Signal wie das inzwischen entfernte 'Mileage' in derselben Botschaft. Kein unabhaengiger Datums-/Uhrzeitkanal auf dem HS-CAN-Bus gefunden. Bits 54-60, ueberlappt NICHT (mehr) mit 'DistanceToService_related' (auf 40-53 gekuerzt, siehe dortiger Kommentar) - kann bei Bedarf unabhaengig weiter untersucht werden.";
CM_ SG_ 1278 IgnitionTick_related "GEFUNDEN (2026-09-21, systematische Suche nach einem Zaehler/Zeitstempel fuers No-RTC-Problem, siehe scripts/can_find_clock_candidate.py + can_clock_persistence_check.py): der mit Abstand regelmaessigste Zaehler unter ueber 600 gepruften unbekannten Feldern - Tick-Periode ueber 3 unabhaengige Stichproben-Logs praktisch IDENTISCH (0,300038s, Konsistenz-Variationskoeffizient 0,000025), Schrittregelmaessigkeit (CV der Tick-Abstaende) 0,049 - deutlich besser als jeder andere Kandidat. Wrapt bei 2047 (11 Bit), steigt monoton mit ca. 3,33Hz (1 Tick alle 300ms). ABER: setzt bei praktisch jeder Zuendung auf 0 zurueck (in >80% der Log-Uebergaenge beobachtet, siehe results/clock_candidates_persistence.csv) - also ein hochpraeziser Betriebszeit-/System-Tick-Zaehler seit Zuendung EIN, KEIN persistenter Zeitstempel. Loest das No-RTC-Problem NICHT (dafuer bräuchte es einen Zaehler, der auch bei Zuendung AUS weiterlaeuft - siehe C000_TOTAL_TIME/0x40A: laeuft zwar ueber alle 34 Logs OHNE Reset durch, aber das ist kumulierte Betriebszeit (pausiert bei Motor aus), keine Wanduhr), aber praezise genug fuer INNERHALB-eines-Logs-Zeitbasis-Zwecke (z.B. Cross-Check der Frame-Zeitstempel-Linearitaet). Vollstaendiges Suchergebnis (kein Kalenderdatum gefunden) siehe docs/logs/can-bus-status.md, Abschnitt 'Zweite Suche nach einem Zaehler/Timestamp'.";
CM_ SG_ 1034 C000_TOTAL_TIME "BESTAETIGT (2026-09-12): laeuft in allen drei verfuegbaren Logs exakt 1:1 mit der echten verstrichenen Zeit mit (candump-2026-09-11_202803: +566.0s Rohwert bei 566.7s Log-Dauer; candump-2026-09-11_180456: +76.0s bei 76.0s; candump-2026-09-12_120952: +218.0s bei 218.4s). Skalierung (0.1,1) und Einheit 'sec' damit bestaetigt echt, kein '_maybe' mehr noetig - vermutlich eine Art kumulierter Betriebszeit-/Uptime-Zaehler des Steuergeraets, nicht notwendigerweise reine Motorlaufzeit (Wertebereich zu diesem Kilometerstand passt nicht zu einer plausiblen Lebenszeit-Motorlaufzeit, eher ein interner Zeitstempel/Zaehler seit einem unbekannten Referenzpunkt).";
CM_ SG_ 1034 BF00_IG_ON_Timer "BESTAETIGT (2026-09-12): zaehlt Sekunden seit Zuendung an (1:1 mit Log-Zeit in allen drei Logs). Starke unabhaengige Kreuzbestaetigung in candump-2026-09-11_180456.log: Zaehler startet bei 191 (Rest einer vorherigen Zuendungsphase), faellt MITTEN im Log auf 0 zurueck - exakt der bereits dokumentierte Moment, in dem die Zuendung wegen nicht getretener Kupplung versehentlich aus/ein ging, bevor der Motor gestartet wurde (siehe Abschnitt 'Erster ~76s-Testdump'). Kein '_maybe' mehr noetig.";
CM_ BO_ 1034 "Reverse-Engineering-Notiz (2026-09-12): Central_Config_Index ist praktisch eine UDS-DID (die Mux-Werte 49152/49153/49408/48896 etc. sind exakt die Hex-Codes 0xC000/0xC001/0xC100/0xBF00...), Byte2-7 die zugehoerige 'ReadDataByIdentifier'-Antwort - erklaert das Namensschema C0xx/BFxx. Von den 41 definierten Sub-Feldern sind C000_TOTAL_TIME/C001_ODO/BF00_IG_ON_Timer/C100-C102(VIN) unabhaengig bestaetigt (siehe jeweilige CM_ SG_-Kommentare). Die restlichen 34 (C103/C104, BF01-BF21 ausser BF00) sind in ALLEN drei verfuegbaren Logs (drei Zeitpunkte, gleiches Fahrzeug) komplett konstant - passt zu statischen Fahrzeug-Konfigurations-/Kalibrierdaten, nicht zu Live-Telemetrie. Auffaellig: viele davon (z.B. BF01=310000000000, BF05=100000000000, BF09=71468259999744) haben nur 1-3 fuehrende Bytes ungleich Null, der Rest durchgehend 00 - womoeglich ist die tatsaechliche UDS-Nutzlast fuer diese DIDs kuerzer als die pauschal angenommenen 48 Bit (Praezedenzfall: BF00 hat sich unabhaengig als echte 16-Bit-Groesse herausgestellt, nicht 48 Bit). NICHT korrigiert/gekuerzt, da mit nur einem Fahrzeugstand nicht unterscheidbar ist, ob die Nullbytes strukturell ungenutzt sind oder nur zufaellig bei diesem Fahrzeug/dieser Konfiguration Null sind - eine Kuerzung waere Raten ohne Beleg. Bliebe offen fuer den Fall, dass mal ein zweites Fahrzeug oder ein Firmware-Update-Log zum Diffen verfuegbar wird.";
CM_ SG_ 120 Longi_Acc_Corr "[G] = [N-0xDF40]/0x7A0";
CM_ SG_ 121 Lateral_Acc_Corr_maybe "[G] = [N-0xDF40]/0x7A0";
CM_ SG_ 121 YawRate_Corr "[deg/s] = [N-0x200]/0x200*114.4";
CM_ SG_ 514 AccPedalPos "Scale /640";
CM_ SG_ 117 Lateral_Acc_Raw "[G]=N*0.001-2";
CM_ SG_ 359 EngineLoad_or_Torque_pct_maybe "UMBENANNT + NEU SKALIERT (2026-09-12), war 'MassAirFlowRate_maybe'. Ursprungsverdacht (2026-09-11): Korrelation mit Gas +0.89, mit MAP (0xFD) allein +0.87, mit dem physikalisch erwarteten Speed-Density-Proxy RPM*MAP nur +0.82 (schwaecher statt staerker als mit MAP allein - untypisch fuer echten MAF). Y-Splitter-Log 2026-09-12 211851 (OBD+CAN gleichzeitig) liefert jetzt die Klaerung: direkte Kalibrierung gegen echten OBD-Luftmassenstrom (g/s) passt schlecht (R2=0.72, Kurve nicht monoton - Sprung raw=80->85). Gegen OBD `ActualEnginePercentTorque` (%) passt dieselbe Formelform dagegen sehr gut (R2=0.96, RMSE 6.1 Prozentpunkte, bester Lag -0.3s): raw*3.17-185.3. Erklaerung: Drehmoment-% ist per Definition '% des bei DIESER Drehzahl moeglichen Maximaldrehmoments', saettigt bei Volllast unabhaengig von der Drehzahl - genau das im Rohwert beobachtete Muster (eng komprimierter Bereich 54-89 nahe Volllast). Echter Luftmassenstrom dagegen skaliert bei Volllast weiter mit der Drehzahl, kein Saettigungsplateau - passt nicht zum beobachteten Muster. Auf EINEM Log kalibriert, nicht ueber mehrere Fahrten cross-validiert. Rohwerte ausserhalb des in diesem Log beobachteten Bereichs (54-89) sind Extrapolation, Formel kann dort ins Negative/>100 laufen - auf 0-100 clippen.";
CM_ SG_ 304 Clutch_Pedal_Position_raw "Eigene Reverse-Engineering-Ergaenzung (nicht Teil des Original-Repos, 2026-09-11): 0=ganz eingekuppelt, ~199=ganz ausgekuppelt. Ueber Korrelation mit dem bekannten StarterInterLockSW-referenzierten Clutch_Related (0x165) gefunden, per RPM-Slip beim Anfahren gegengeprueft (Reibphase bei raw~114-123 = ~59% getreten, nah am unabhaengig bekannten ~55%-Bisspunkt aus alten OBD-Logs). Lineare 0-100%-Skalierung wahrscheinlich, aber NICHT durch Referenzmessung bestaetigt.";
CM_ SG_ 117 YawRate_Raw "[deg/s]=N*0.01-180";
CM_ SG_ 118 Longitudinal_Acc_Raw "[G]=N*0.001-2";
CM_ SG_ 1266 HUD_Height "Min[+] 0x00C5, Max[-] 0x0DC5";
CM_ BO_ 1266 "Eigene Reverse-Engineering-Korrektur (2026-09-12), BITKONFLIKT-FIX: Original enthielt zusaetzlich 'SG_ HUD_Bright : 35|4@0+', das die unteren 4 Bit von Byte4 beanspruchte - genau die Bits, die HUD_Height (27|12@0+, Byte3 Bit27-24 + Byte4 komplett) fuer sein unteres Nibble ebenfalls braucht. Gleicher Fehlertyp wie bei LIGHT@0x91 (siehe dort): cantools zaehlt die ueberlappenden Bits doppelt und wirft bei JEDEM Frame 'Short data', wodurch 0x4F2 komplett unlesbar war (auch fuer das gut dokumentierte HUD_Height mit bekanntem Wertebereich 0x00C5-0x0DC5). HUD_Bright ENTFERNT statt verschoben, da seine echte Position unbekannt ist - die Botschaft hat drei komplett freie Bytes (0,1,2) und drei weitere (5,6,7) sowie 3 freie Bits in Byte3 (31-29), eine neue Position waere reines Raten ohne Beleg. Nach Entfernen verifiziert gegen candump-2026-09-12_120952.log + candump-2026-09-11_180456.log: alle 2663 Frames dekodieren fehlerfrei, HUD_Height liegt bei 1797-1861 (0x705-0x745) - konsistent innerhalb des oben dokumentierten Original-Wertebereichs. HUD_Bright muesste bei Bedarf ueber einen gezielten Test (HUD-Helligkeit am Fahrzeug verstellen, welches der freien Bytes sich aendert) neu lokalisiert werden.";
VAL_ 145 HAZ_SW 0 "Off" 1 "On";
VAL_ 145 WIP_F_INT 0 "0" 30 "1" 50 "2" 70 "3" 90 "4";
VAL_ 145 TURN_SW 2 "L" 0 "Off" 1 "R";
VAL_ 145 FOG_SW 0 "Off" 1 "Rear" 2 "Front" 3 "Front_Rear";
VAL_ 145 RearWiper 3 "INT" 1 "ON" 0 "Off";
VAL_ 145 Washer 0 "Off" 1 "Rear" 2 "Front" 3 "Front+Rear";
VAL_ 145 FrontWiper 0 "Off" 1 "ON" 2 "HI" 3 "INT";
VAL_ 145 LIGHT 769 "Off" 768 "AUTO" 896 "TNS" 960 "HEAD";
VAL_ 80 KeyState 0 "OFF" 1 "ACC" 2 "ON" 3 "START";
VAL_ 80 KeyStateInv 5 "ACC" 7 "OFF" 3 "ON" 0 "START";
VAL_ 157 CRU_CON_SW1 0 "Not_Pressed" 4 "OFF_CANC" 128 "Set_(Dn)" 64 "Set_(Up)" 1 "ON_MODE" 16 "Resume" 256 "Distance_(Up)" 512 "Distance_(Dn)";
VAL_ 628 INFO_SW 0 "Off" 1 "SW1(Up)" 2 "SW2(Dn)" 3 "SW3(INFO)";
VAL_ 628 Key_hold 1 "Hold_key_close_to_start_button" 0 "-";
VAL_ 628 Key_notfound 1 "Key_not_found" 0 "-";
VAL_ 628 IC_Buzz 0 "No Description" 1 "P-P-" 2 "P-P-x3" 3 "PPx6";
VAL_ 628 Key_Batt 1 "Key_Battery_is_low" 0 "-";
VAL_ 628 Key_fob 5 "Lock" 6 "Unlock";
VAL_ 158 DSC_OFF_Switch 0 "Not_Pressed" 1 "Pressed";
VAL_ 158 LDWS_ON_Switch 0 "Not_Pressed" 1 "Pressed";
VAL_ 158 BSM_RVM_ON_Switch 1 "Pressed" 0 "Not_Pressed";
VAL_ 158 iStop_OFF_Switch 0 "Not_Pressed" 1 "Pressed";
VAL_ 159 Parking_Brake 0 "Released" 1 "Applied";
VAL_ 606 SpeedUnit 0 "km/h" 1 "mph";
VAL_ 606 StopVehicle 0 "" 1 "Stop_Vehicle_at_safe_area";
VAL_ 606 DAA_Related 6 "RecommendRest";
VAL_ 1034 Central_Config_Index 49152 "C000" 49153 "C001" 49408 "C100" 49409 "C101" 49410 "C102" 49411 "C103" 49412 "C104" 48896 "BF00" 48897 "BF01" 48898 "BF02" 48899 "BF03" 48900 "BF04" 48901 "BF05" 48902 "BF06" 48903 "BF07" 48904 "BF08" 48905 "BF09" 48906 "BF0A" 48907 "BF0B" 48908 "BF0C" 48909 "BF0D" 48910 "BF0E" 48911 "BF0F" 48912 "BF10" 48913 "BF11" 48914 "BF12" 48915 "BF13" 48916 "BF14" 48917 "BF15" 48918 "BF16" 48919 "BF17" 48920 "BF18" 48921 "BF19" 48922 "BF1A" 48923 "BF1B" 48924 "BF1C" 48925 "BF1D" 48926 "BF1E" 48927 "BF1F" 48928 "BF20" 48929 "BF21";
VAL_ 1147 BSM_Status 1 "On" 0 "Off";
VAL_ 1045 DSC_Status 0 "Off" 1 "On";
VAL_ 154 F_FOG_RELAY 1 "On" 0 "Off";
VAL_ 154 Headlight 0 "Off" 2 "TNS" 3 "TNS_Lo" 12 "Hi";

VAL_ 154 Turn 0 "Off" 2 "R" 1 "L" 3 "LR";
VAL_ 154 PanelLight 0 "Day" 1 "Night";
VAL_ 1086 R_FOG_LAMP 1 "On" 0 "Off";
VAL_ 1086 Trunk 0 "Closed" 1 "Open";
VAL_ 1086 DoorRight 0 "Closed" 1 "Opened";
VAL_ 1086 DoorLeft 0 "Closed" 1 "Opened";
VAL_ 540 LDWS_Status1 0 "Off" 1 "On";
VAL_ 540 LDWS_Status2 0 "Off" 1 "On";
VAL_ 540 SCBS_SBS_Status 0 "On" 1 "Off";
VAL_ 1157 SCBS_SBS_Status 2 "On" 1 "Off";
VAL_ 253 MAP_Manifold_absolute_pressure_sensor 257 "Invalid" 10 "10_or_below" 115 "115_or_higher";
VAL_ 357 MT_Gear_Select 1 "InGear" 2 "Neutral";
CM_ SG_ 357 MT_Gear_Select "BESTAETIGT (2026-09-12): loest die N/1st-Mehrdeutigkeit von MT_Gear_Position auf. Gegen candump-2026-09-11_202803.log (echte Fahrt) geprueft: jedes Mal wenn MT_Gear_Position='N/1st' UND MT_Gear_Select='InGear' zeigt, beschleunigt das Fahrzeug anschliessend aus niedriger Geschwindigkeit (klassisches Anfahren im 1. Gang, z.B. t=16.8s: RPM~1293, Speed~10.1 km/h und steigend); jedes Mal wenn Select='Neutral' zeigt, rollt das Fahrzeug ohne Vortrieb aus oder steht (z.B. t=334-340s beim Ausrollen zum Stillstand). Im Stand-Test candump-2026-09-12_120952.log (kein Gang eingelegt lt. Nutzer) zeigt Select durchgehend 'Neutral' - deckt sich. Praktische Regel: MT_Gear_Position='N/1st' + Select='Neutral' -> echt Neutral; MT_Gear_Position='N/1st' + Select='InGear' -> 1. Gang eingelegt. Physikalisch plausibel (typischer Neutral-/Rueckfahrlicht-Schalter am H-Schaltgetriebe, unabhaengig von der eigentlichen Gangpositions-Sensorik).";

VAL_ 357 CC_Mode_Related 0 "OFF" 1 "ON";
VAL_ 357 CC_Mode_Related2 0 "OFF" 1 "ON";
VAL_ 357 MT_Gear_Position 19 "N/1st" 11 "2nd" 7 "3rd" 6 "4th" 5 "5th" 3 "6th";
SG_MUL_VAL_ 1034 C000_TOTAL_TIME Central_Config_Index 49152-49152;
SG_MUL_VAL_ 1034 C001_ODO Central_Config_Index 49153-49153;
SG_MUL_VAL_ 1034 C100_VIN_1_6 Central_Config_Index 49408-49408;
SG_MUL_VAL_ 1034 C101_VIN_7_12 Central_Config_Index 49409-49409;
SG_MUL_VAL_ 1034 C102_VIN_13_17 Central_Config_Index 49410-49410;
SG_MUL_VAL_ 1034 C103 Central_Config_Index 49411-49411;
SG_MUL_VAL_ 1034 C104 Central_Config_Index 49412-49412;
SG_MUL_VAL_ 1034 BF00_IG_ON_Timer Central_Config_Index 48896-48896;
SG_MUL_VAL_ 1034 BF01 Central_Config_Index 48897-48897;
SG_MUL_VAL_ 1034 BF02 Central_Config_Index 48898-48898;
SG_MUL_VAL_ 1034 BF03 Central_Config_Index 48899-48899;
SG_MUL_VAL_ 1034 BF04 Central_Config_Index 48900-48900;
SG_MUL_VAL_ 1034 BF05 Central_Config_Index 48901-48901;
SG_MUL_VAL_ 1034 BF06 Central_Config_Index 48902-48902;
SG_MUL_VAL_ 1034 BF07 Central_Config_Index 48903-48903;
SG_MUL_VAL_ 1034 BF08 Central_Config_Index 48904-48904;
SG_MUL_VAL_ 1034 BF09 Central_Config_Index 48905-48905;
SG_MUL_VAL_ 1034 BF0A Central_Config_Index 48906-48906;
SG_MUL_VAL_ 1034 BF0B Central_Config_Index 48907-48907;
SG_MUL_VAL_ 1034 BF0C Central_Config_Index 48908-48908;
SG_MUL_VAL_ 1034 BF0D Central_Config_Index 48909-48909;
SG_MUL_VAL_ 1034 BF0E Central_Config_Index 48910-48910;
SG_MUL_VAL_ 1034 BF0F Central_Config_Index 48911-48911;
SG_MUL_VAL_ 1034 BF10 Central_Config_Index 48912-48912;
SG_MUL_VAL_ 1034 BF11 Central_Config_Index 48913-48913;
SG_MUL_VAL_ 1034 BF12 Central_Config_Index 48914-48914;
SG_MUL_VAL_ 1034 BF13 Central_Config_Index 48915-48915;
SG_MUL_VAL_ 1034 BF14 Central_Config_Index 48916-48916;
SG_MUL_VAL_ 1034 BF15 Central_Config_Index 48917-48917;
SG_MUL_VAL_ 1034 BF16 Central_Config_Index 48918-48918;
SG_MUL_VAL_ 1034 BF17 Central_Config_Index 48919-48919;
SG_MUL_VAL_ 1034 BF18 Central_Config_Index 48920-48920;
SG_MUL_VAL_ 1034 BF19 Central_Config_Index 48921-48921;
SG_MUL_VAL_ 1034 BF1A Central_Config_Index 48922-48922;
SG_MUL_VAL_ 1034 BF1B Central_Config_Index 48923-48923;
SG_MUL_VAL_ 1034 BF1C Central_Config_Index 48924-48924;
SG_MUL_VAL_ 1034 BF1D Central_Config_Index 48925-48925;
SG_MUL_VAL_ 1034 BF1E Central_Config_Index 48926-48926;
SG_MUL_VAL_ 1034 BF1F Central_Config_Index 48927-48927;
SG_MUL_VAL_ 1034 BF20 Central_Config_Index 48928-48928;
SG_MUL_VAL_ 1034 BF21 Central_Config_Index 48929-48929;

CM_ SG_ 535 VehicleSpeed_ABS_raw "Eigene Reverse-Engineering-Ergaenzung (2026-09-11), WAHRSCHEINLICH: Byte4-5 (BE) korreliert mit VehicleSpeed@0x202 (BO_514) bei identischer Skalierung (0.01 km/h/count, kein Offset) mit r=1.000 im Fahr-Log (candump-2026-09-11_202803), Restfehler <3 km/h (vermutlich nur Abtast-Zeitversatz). Redundante Geschwindigkeit direkt vom ABS-Modul. Methode: ganzes-Log-Korrelation gegen bekannten Anker + lineare Regression, siehe Analysebericht.";
CM_ SG_ 304 EngineRPM_related_2 "Eigene Reverse-Engineering-Ergaenzung (2026-09-11), WAHRSCHEINLICH: Byte5-6 (BE) korreliert mit EngineRPM@0x202 bei Skalierung 0.5 rpm/count (r=0.9999 unbereinigt, r=0.845 nach Entfernen des ueberlagerten Langzeit-Trends -> echte, nicht nur trend-bedingte Kopplung). Resid_std~7.5 rpm, Resid_max~594 rpm bei schnellen Drehzahlaenderungen - vermutlich eine leicht anders gefilterte/verzoegerte RPM-Variante, nicht bitidentisch mit der Haupt-RPM. UNSICHER bzgl. exakter Bedeutung (evtl. Ziel-/Soll-Drehzahl statt Ist-Drehzahl).";
CM_ SG_ 358 Clutch_Pedal_Position_related_2 "Eigene Reverse-Engineering-Ergaenzung (2026-09-11), WAHRSCHEINLICH: Byte0 korreliert nahezu perfekt mit Clutch_Pedal_Position_raw@0x130 (r=0.9987 unbereinigt, r=0.998 nach Trendbereinigung - eindeutig echte Kopplung, kein Trend-Artefakt). Skalierung empirisch per linearer Regression bestimmt (raw_hier = 0.8 * Clutch_Pedal_Position_raw, hier umgekehrt als *1.25 dargestellt). Vermutlich redundante/andere Aufloesung des Kupplungspedalwegs.";
CM_ SG_ 120 BrakePressure "ERGAENZUNG (2026-09-11) zur bestehenden Skalierung: Web-Quelle (timurrrr/RaceChronoDiyBleDevice, lokal data/can/mazda_mx5_nd.md) dokumentiert fuer dieselbe Botschaft (0x78, 2019er MX-5) eine alternative Bremspedal-%-Formel min(max(bitsToUInt(raw,28,12)-156,0)/2.56,100), was in DBC-Motorola-Notation Bit 27|12@0+ entspricht. Diese 12-Bit-Spanne UEBERLAPPT Byte4 vollstaendig mit BrakePressure (39|16) - kann daher nicht als eigenes SG_ ergaenzt werden (cantools bricht sonst das Decoding der ganzen Botschaft ab wegen echter Bit-Ueberlappung). Cross-Check: mit dieser Formel von Hand aus den Rohbytes berechnet korreliert der %-Wert mit der hier dekodierten BrakePressure mit r=0.998 im Fahr-Log (Wertebereich in diesem Log nur bis 31%, kein Rolloverereignis aufgetreten) - beide Interpretationen beschreiben vermutlich denselben Rohsensor nur mit unterschiedlicher Bitbreite/Skalierung. Formel manuell nachrechenbar, nicht als SG_ eingetragen.";
CM_ SG_ 512 EngineLoad_related_maybe "Eigene Reverse-Engineering-Ergaenzung (2026-09-11), VERMUTUNG: Byte0-1 (BE) korreliert mit EngineLoad_or_Torque_pct_maybe@0x167 (r=0.85 unbereinigt, r=0.66 nach Trendbereinigung -> Korrelation ist NICHT nur Trend-Artefakt, echte Kurzzeitdynamik-Kopplung vorhanden; damals hiess der Kanal noch 'MassAirFlowRate_maybe', siehe dessen aktualisierter Kommentar zur Umbenennung 2026-09-12). Selbst noch unskaliert/unsicher, aber passt zur selben Last-/Drehmoment-Domaene. Sender/Domaene (HS_PCM) passt zu Last-bezogenen Groessen.";
CM_ SG_ 576 SteeringTorque_related "ERGAENZUNG (2026-09-11) zur bestehenden Unsicherheits-Markierung: Quelle Web (mx5things.blog/2017/02/18/can-bus-sniffer) nennt Byte1 dieser Botschaft (0x240) als 'steering torque' ohne Formel - Byte1 ist die untere Haelfte dieses bereits vorhandenen 16-bit-Signals (Byte0-1). Eigene Cross-Validation: Byte1 allein korreliert mit der Aenderungsrate von Steering_Wheel_Absolute_Angle@0x82 (|Lenkrate|) mit r~0.71 (unbereinigt) bzw. r~0.4 (nach Trendbereinigung, win=10s) - deutlich staerker als mit dem Winkel selbst (r~0.46-0.57) - physikalisch plausibel fuer ein Lenkmoment/EPAS-Unterstuetzungssignal. Staerkt die Web-Hypothese fuer dieses Signal, Skalierung/Einheit weiterhin unbekannt.";
CM_ SG_ 576 SteeringAngle_related_2_maybe "Eigene Reverse-Engineering-Ergaenzung (2026-09-11), VERMUTUNG (moderat): Byte4 (eigenstaendig, kein Ueberlapp mit SteeringTorque_related) korreliert mit Steering_Wheel_Absolute_Angle@0x82 mit r~0.57-0.68 (unbereinigt, methodenabhaengig), r~0.40 nach Trendbereinigung - schwaecher aber real. Sender HS_EPAS passt zu einer weiteren lenkwinkelbezogenen Groesse (z.B. grob quantisierter/gefilterter Winkel oder Rate). Keine Skalierung bekannt.";
CM_ SG_ 576 SteeringTorque_related "KORREKTUR (2026-09-12): Bit-Definition von 16 Bit (Byte0-1) auf 8 Bit (nur Byte1) verkleinert. Systematischer Scan aller Byte-Positionen/Endianness/Vorzeichen dieser Botschaft gegen |Lenkrate| von Steering_Wheel_Absolute_Angle@0x82 zeigt: Byte1 allein r=0.81, Byte0 allein r=0.04 (reines Rauschen) - das volle 16-Bit-Feld verduennte die Korrelation nur (vorher dokumentierte r~0.71 fuer den 16-Bit-Wert). Byte0 ist unklaimed, moeglicherweise ein separates, noch nicht identifiziertes Signal.";
CM_ SG_ 120 BrakePressure "KORREKTUR (2026-09-12): Bisheriger 'Rollover-Bug' war ein Vorzeichenfehler, kein Rollover. Bit-Definition von unsigned (@0+) auf signed (@0-) geaendert, Formel (Faktor/Offset) unveraendert. Beleg: Vollbremsung in candump-2026-09-12_155117.log (t=9.83-10.09s) - unsigned-Rohwert steigt 56771->63939, 'faellt' dann auf 451 (der bekannte Bug), signed-Rohwert dagegen glatt durchgehend -8765->-1597->451->8131, keine Unstetigkeit. Mit signed und der alten Formel (raw*0.001-40) durchgehend -67.2 bis -27.0 bar in diesem Fenster - der bislang dokumentierte externe Korrekturhack (+65535 bei Spruengen >30000) ist damit ueberfluessig. Absolutkalibrierung (warum der Ruhewert um -40 bar statt nahe 0 liegt) blieb an dieser Stelle noch ungeklaert.";
CM_ SG_ 120 BrakePressure "ABSOLUTKALIBRIERUNG KORRIGIERT (2026-09-12): Y-Splitter-Log 2026-09-12 211851 (OBD+CAN gleichzeitig) liefert erstmals einen echten Referenzkanal fuer denselben physikalischen Druck: `BFP_PRE_MZ` (OBD, 'Brake Fluid Pressure Sensor', kPa). Direkter Soll-Ist-Vergleich zeigt: mit der alten Formel (0.001,-40) liegt der Ruhewert (92.6% der BFP_PRE_MZ-Samples sind exakt 0 kPa, haeufigster Rohwert -26429) bei ca. -66.4 bar - physikalisch unmoeglich fuer eine Druckmessung. Neu kalibriert per Lag-Suche (+Regression, bester Lag -0.3s) direkt gegen BFP_PRE_MZ: Faktor 0.0012413 (statt 0.001), Offset +32.7986 (statt -40) - Vorzeichen des Offsets war falsch, nicht nur die Groesse. Neue Formel trifft den Ruhewert korrekt (Vorhersage bei raw=-26429: ~0 bar) und passt mit R²=0.986 (RMSE 0.57 bar) ueber die gesamte Fahrt inkl. mehrerer Bremsereignisse. Nur an diesem einen Log kalibriert, keine Cross-Validation ueber mehrere Fahrten. Min/Max-Feld auf [0|45] gesetzt (deckt den beobachteten Bereich ab, physikalisch sinnvoll fuer Bremsdruck).";
CM_ SG_ 1143 GearDisplay_related_maybe "Eigene Reverse-Engineering-Ergaenzung (2026-09-11), VERMUTUNG (schwach): Byte1 korreliert mit MT_Gear_Position@0x165 (r=-0.83 unbereinigt, r=-0.34 nach Trendbereinigung - deutlich schwaecher, aber nicht verschwunden). Nur 3 unterschiedliche Rohwerte im Log (0/1/2) - vermutlich ein grob quantisierter Anzeige-/Bereichs-Indikator (z.B. Schaltempfehlungs-Zone im Kombiinstrument), nicht die praezise Gangposition selbst. Sender HS_IC (Kombiinstrument) passt zu einer Anzeigegroesse.";
CM_ SG_ 80 StarterInterLockSW "ERGAENZUNG (2026-09-11): Byte3 dieser Botschaft (0x50) als Ganzes (nicht nur Bit25=StarterInterLockSW) korreliert binaer mit Clutch_Pedal_Position_raw@0x130 (r=0.88 unbereinigt, r=0.69 nach Trendbereinigung) - deckt sich mit der erwarteten Funktion von StarterInterLockSW (loest nahe des Kupplungs-Greifpunkts aus). Vermutlich ist die beobachtete Korrelation identisch mit diesem bereits benannten Bit, kein zusaetzliches Signal in den uebrigen 7 Bits von Byte3 gefunden.";
CM_ SG_ 1086 ROOM_FUSE "ERGAENZUNG (2026-09-11), RUECKZUG einer Vermutung: Byte6 dieser Botschaft (0x43e) als Ganzes zeigte zunaechst eine Korrelation mit BrakePressure@0x78 (r=0.85 unbereinigt, r=0.41 nach Trendbereinigung), die als moeglicher Bremslicht-/Bremsschalter interpretiert wurde. Byte6 enthaelt aber bereits das benannte Bit ROOM_FUSE (Bit51, Innenraumlicht-Sicherung) - die Korrelation stammt hoechstwahrscheinlich von diesem bereits bekannten, thematisch unabhaengigen Signal (zufaellige zeitliche Naehe zu Bremsungen in diesem einen Log, z.B. durch Tuer-/Lichtbedienung). KEIN eigenstaendiger Bremsschalter-Fund, Hypothese verworfen.";
CM_ SG_ 117 HardBrakingEvent_flag_maybe "Eigene Reverse-Engineering-Ergaenzung (2026-09-11), VERMUTUNG (Ereignis-Flag, NICHT Beschleunigungswert): Byte1 (binaer) korreliert stark mit Longi_Acc_Corr@0x78 (r=-0.97), ABER Gegenprobe gegen den sauberen Longitudinal_Acc_Raw@0x76 (RCM) ergibt r~0.0002 - die scheinbare Korrelation ist ein Artefakt der bekannten Skalierungs-/Rollover-Anomalie von Longi_Acc_Corr (siehe dortige Notiz), nicht echte g-Kraft-Kopplung. Da das Flag exakt bei denselben harten Bremsereignissen kippt wie die Longi_Acc_Corr-Ausreisser, ist ein Verzoegerungs-/Ereignis-Schwellwert-Flag plausibel (z.B. RCM Pre-Crash/Gurtstraffer-Vorstufe - HS_RCM ist typischerweise das Rueckhaltesystem-Steuergeraet). Niedrige Konfidenz, nur 3 Ereignisse im Log.";
CM_ SG_ 832 PassengerSeatbelt_Buckled "Eigene Reverse-Engineering-Ergaenzung (2026-09-20), BESTAETIGT (Gurtschloss-Schalter, KEINE Gewichts-/Sitzbelegungserkennung): Bitlage aus opendbc mazda_2017.dbc (PASSENGER_SEATBELT, Bit26 little-endian) uebernommen, gegen eigene Freitagslogs (18.09.) mit Nutzer-Zeitangaben geprueft. candump-2026-09-18_093544.log: Bit kippt exakt bei t+35.3s (Motorstart+Einstieg/Anschnallen laut Nutzer) auf 1 und bei t+745.2s (Ausstieg nach Abschnallen) auf 0. candump-2026-09-18_090404.log: Gurt nur um einen Pi zu halten (kein Insasse), Bit bleibt konstant 1 - Beleg dafuer, dass es rein am Schlossschalter haengt, nicht am Gewicht. candump-2026-09-18_170350.log/_171150.log (Folgefahrt mit Beifahrer, vom Nutzer bestaetigt): Bit kippt bei t+130.3s auf 1 bzw. bei t+393.7s auf 0 - zweites unabhaengiges Log. Kein Test fuer den Fall 'besetzt, aber nicht angeschnallt' (genau das Szenario der Gurtwarnung) - dafuer braeuchte es eine gezielte Testfahrt, siehe docs/logs/can-bus-status.md 2026-09-20.";
CM_ SG_ 832 PassengerSeatOccupied_maybe "Eigene Reverse-Engineering-Ergaenzung (2026-09-20), VERMUTUNG (Gewichts-/Sitzbelegungssensor, unabhaengig vom Gurtschloss - noch NICHT final bestaetigt, da der vierte erwartete Zustand 'besetzt+Gurt offen' noch nie beobachtet wurde): Byte2 Bit0 (=Bit16) ist Teil eines 4-Bit-Zustandscodes (Byte2 low-Nibble + Byte3 high-Nibble), der nach einer Anlauf-/Kalibrierphase von 60-70s (fester Bezug zum Motorstart, nicht zum Gurt- oder Tuerereignis) auf genau 2 stabile Werte einpendelt: Bit16=1 bei echtem Beifahrer (candump-2026-09-18_093544.log t+65s bis t+745s, candump-2026-09-18_170350/_171150/_161130/_162411/_165510/_155230, candump-2026-09-19_163755/_233436, candump-2026-09-12_150619/_155117, candump-2026-09-17_125935/_131635/_133436 - alle vom Nutzer als 'mit Beifahrer' bestaetigt), Bit16=0 wenn leer. Entscheidender Gegenbeleg gegen 'ist nur der Gurtschalter': candump-2026-09-18_090404.log (Gurt nur um einen Pi geschnallt, KEIN Insasse) erreicht trotz geschlossenem Gurt einen ANDEREN Code (Byte3-High-Nibble 0x9 statt 0x6/0x2 bei echtem Beifahrer) und Bit16 bleibt durchgehend 0 - das Feld unterscheidet also 'Gurt zu' von 'wirklich besetzt'. Beim eindeutig dokumentierten Ausstiege-Ereignis (093544, Gurt auf bei t+745.2s, Tuer auf bei t+750.6s, Tuer zu bei t+772.5s) kippt Bit16 bei t+763.66s auf 0 - sauber zwischen Tuerauf und Tuerzu, passt zum echten Verlassen des Sitzes. Zeitaufgeloeste Auswertung ueber alle Pi-CAN-Logs (Sessions an >60s-Luecken gesplittet, erste 80s je Session ignoriert): 2.55h Bit16=1 vs. 6.19h Bit16=0 - deckt sich mit der Erwartung des Nutzers, insgesamt deutlich mehr Solo- als Beifahrerzeit gefahren zu sein. Offener Punkt: der vierte Zustand 'besetzt, Gurt NICHT geschlossen' (das eigentliche Warnszenario) fehlt noch in allen Logs - geplante Testfahrt (Beifahrer sitzt bewusst kurz unangeschnallt) steht noch aus, siehe docs/status/can-bus.md.";
CM_ SG_ 118 HardBrakingEvent_flag_maybe "Siehe CM_ SG_ 117 HardBrakingEvent_flag_maybe - identisches Byte/Verhalten, in beiden RCM-Botschaften (0x75 und 0x76) vorhanden.";
CM_ SG_ 1045 DSC_Indicator_maybe "Eigene Reverse-Engineering-Ergaenzung (2026-09-26). Byte0 von 0x415 ist ein Kontrollleuchten-Byte: 114 (0x72) fuer genau 25 Frames (~2,5 s) nach Zuendung EIN = Lampentest, 98 (0x62) fuer 1 Frame beim Abstellen, 0 im Betrieb - und 6 (Bits 1+2) ausschliesslich waehrend der Traktionseingriffe (6 Episoden, deckungsgleich mit TCS_TorqueRequest_maybe auf 0x211). Deutung: DSC-Kontrollleuchte, 3 = blinkt wegen Regeleingriff, 1 = an (Lampentest). Die Bits 4-6 sind nur im Lampentest gesetzt; DAMIT IST AUCH DSC_Status (Bit 4) erklaert: es ist eine Kontrollleuchte (vermutlich 'DSC OFF'), die nur beim Lampentest leuchtet - der Wert 0 heisst 'Leuchte aus = DSC aktiv', nicht 'DSC aus'. Fahrzeugtest: Lampentest und Leuchte bei einem Eingriff beobachten.";
CM_ SG_ 1045 BrakeRelated_weak_maybe "Eigene Reverse-Engineering-Ergaenzung (2026-09-11), VERMUTUNG (schwach): Byte1 korreliert schwach mit BrakePressure@0x78 (r=0.65 unbereinigt, r=0.30 nach Trendbereinigung). Sender HS_ABS und Botschaft enthaelt bereits DSC_Status - ein weiteres bremsbezogenes Signal ist plausibel, aber Korrelation zu schwach fuer verlaessliche Aussage. Zur weiteren Pruefung.";
CM_ SG_ 121 MsgCounter_maybe "Eigene Reverse-Engineering-Ergaenzung (2026-09-11), STRUKTURELL (kein Messwert): Byte, das ueberwiegend um genau +1 (mod 256) je Frame ansteigt (>93% der Samples) - klassisches Muster eines Nachrichten-/Lebenszeichenzaehlers. Gleiches Muster in mehreren Botschaften auf Byte6 beobachtet (u.a. 0x217, 0x21e, 0x325, 0x344), Wertebereich unterschiedlich breit je nach beobachteter Logdauer. Kein physikalischer Messwert.";
CM_ SG_ 145 MsgCounter_maybe "Eigene Reverse-Engineering-Ergaenzung (2026-09-11), STRUKTURELL (kein Messwert): Byte3 zeigt einen 4-Bit-Rollzaehler (0-15, wrapt vollstaendig im Log). Kein physikalischer Messwert, vermutlich Lebenszeichen-/Sequenzzaehler.";
CM_ SG_ 145 LIGHT "Eigene Reverse-Engineering-Korrektur (2026-09-12), BITLAENGE-FIX: Original war 7|10@0+ (10 Bit ab Bit7, Byte0 komplett + Bit15-14 von Byte1). Das ueberlappt zwangslaeufig FOG_SW (Bit1-0 in Byte0): cantools baut fuer alle big-endian-Signale einer Botschaft EIN gemeinsames Packformat und geht dabei von ueberlappungsfreien Signalen aus - durch den Overlap zaehlt es Bit1-0 doppelt, kommt auf mehr als 64 Bit Gesamtlaenge und wirft bei JEDEM Frame 'ValueError: Short data' / DecodeError. Botschaft 0x91 (und damit auch TURN_SW/HAZ_SW/die Wischer-Signale) wurde dadurch seit jeher in der gesamten Pipeline komplett uebersprungen (can_log_parser.py's pauschales except schluckt das lautlos). Auf 7|6@0+ (Bit7 bis Bit2, nur Byte0) gekuerzt - das sind die einzigen mit FOG_SW ueberlappungsfreien Bits ab Startbit 7, dekodiert jetzt ohne Fehler. Gegen candump-2026-09-12_120952.log verifiziert (ganzes Log, ID 0x91): genau 4 saubere, haeufige Werte 48/56/60/62 (binaer 110000/111000/111100/111110, klassisches Thermometer-/Balkencode-Muster, konsistent mit einer Lichtschalter-Raststufung), keine Ueberlappungsfehler mehr. WICHTIG: die VORHANDENE VAL_ 145 LIGHT Tabelle (769=Off/768=AUTO/896=TNS/960=HEAD) wurde fuer das ALTE 10-Bit-Feld erstellt und passt NICHT mehr zum gekuerzten 6-Bit-Feld (max. Rohwert jetzt 63) - sie ist damit unerreichbar/veraltet, aber bewusst NICHT angepasst, da eine korrekte Neuzuordnung (v.a. was aus 'Off' vs 'AUTO' wird, die im alten Feld nur ueber das jetzt entfernte Bit14 von Byte1 unterschieden wurden) eine echte Bedeutungs-Interpretation waere und keine reine Bitlaengen-Korrektur mehr. Cross-Check TURN_SW (unveraendert, Bit13-12) gegen Turn@0x9A: in den bekannten Blinkerfenstern aus candump-2026-09-12_120952.log (L: t=78,4-84,2s / R: t=85,6-90,0s, siehe mx5_can_bus_status.md) zeigt TURN_SW jetzt durchgehend die erwarteten Werte 'L' bzw. 'R' synchron zu den Blinkphasen auf 0x9A - keine unabhaengige Ueberpruefung von LIGHTs Skalierung/Bedeutung selbst, daher weiterhin als unsicher zu behandeln (_maybe-Status implizit, da die einzige bekannte Referenz - die alte VAL_-Tabelle - nicht mehr gilt).";
CM_ SG_ 254 MsgCounter_maybe "Eigene Reverse-Engineering-Ergaenzung (2026-09-11), STRUKTURELL (kein Messwert): Byte6 zeigt einen 4-Bit-Rollzaehler (0-15, wrapt vollstaendig im Log).";
CM_ SG_ 254 SlowlyVarying_unclear "Eigene Reverse-Engineering-Ergaenzung (2026-09-11), UNGEKLAERT: Byte7 aendert sich langsam in engem Band (67-82), erfuellt formal das Rollzaehler-Kriterium (haeufig +1), aber der schmale, nicht-wrappende Wertebereich passt nicht zum klassischen 4-Bit-Muster. Keine Korrelation zu bekannten Kanaelen gefunden. Zur manuellen Pruefung.";
CM_ SG_ 542 MsgCounter_maybe "Eigene Reverse-Engineering-Ergaenzung (2026-09-11), STRUKTURELL (kein Messwert): Byte6 zeigt einen 4-Bit-Rollzaehler (0-15, wrapt vollstaendig im Log), gleiches Muster wie bei 0x217/0x325/0x344.";
CM_ SG_ 805 MsgCounter_maybe "Eigene Reverse-Engineering-Ergaenzung (2026-09-11), STRUKTURELL (kein Messwert): Byte6 zeigt einen 4-Bit-Rollzaehler (0-15, wrapt vollstaendig im Log), gleiches Muster wie bei 0x217/0x21e/0x344.";
CM_ BO_ 1080 "Eigene Reverse-Engineering-Ergaenzung (2026-09-11): 0x438, NICHT im Original-DBC (Sender/BU_ unbekannt, daher Platzhalter UNKNOWN_ECU verwendet). Payload ist in BEIDEN Logs konstant '44 30 31 36 39 30 51 4B' = ASCII 'D01690QK' - vermutlich Teilenummer-/Kalibrierungskennung, Sendeintervall ~1s. Nicht fahrdynamik-relevant.";
CM_ BO_ 836 "Eigene Reverse-Engineering-Ergaenzung (2026-09-11): 0x344, NICHT im Original-DBC (Sender/BU_ unbekannt). Byte0 binaeres Flag (0/64), Byte6 4-Bit-Rollzaehler (0-15), Byte7 langsam variierend (232-255, 24 Werte) - keine Korrelation zu bekannten Kanaelen gefunden. Restliche Bytes konstant. Zur manuellen Pruefung.";
CM_ BO_ 1169 "Eigene Reverse-Engineering-Ergaenzung (2026-09-11): 0x491, NICHT im Original-DBC (Sender/BU_ unbekannt). Payload durchgehend 00 00 00 00 00 00 00 00 bei hoher Frequenz (~33 Hz) in beiden Logs - vermutlich Heartbeat/Keep-Alive ohne Nutzinformation.";
CM_ SG_ 120 YawRate_related "Eigene Reverse-Engineering-Ergaenzung (2026-09-14), scripts/can_byte_search.py, CROSS-LOG BESTAETIGT (5/5 Logs mit Traffic: candump-2026-09-12_155117/211833, candump-2026-09-14_081105/163711/173057). Byte2-3 (16-bit signed BE) korreliert mit YawRate_Raw@0x75 (RCM, validierter Referenzkanal) mit Spearman r_detrended=0.84-0.97 je Log. Formel per linearer Regression gegen YawRate_Raw auf candump-2026-09-14_081105.log (R²=0.91): 0.0011*raw+0 deg/s, aehnliche Fits (0.0009-0.0011) auf den anderen Logs, Offset durchgehend nahe 0. Botschaft 0x78 (HS_ABS) enthaelt bereits die bekannt fehlerhaften Longi_Acc_Corr/Lateral_Acc_Corr_maybe - plausibel, dass das ABS/ESP-Modul hier eine eigene (moeglicherweise gefilterte) Gierrate fuehrt. NICHT redundanzgeprueft gegen einen zweiten ABS-eigenen Kanal, da keiner bekannt ist. Formel nur ungefaehr, nicht so praezise wie die RCM-Referenz selbst - fuer Praezisionsanwendungen weiter YawRate_Raw@0x75 nutzen, dieser Kanal ist v.a. interessant als potenzieller Ansatzpunkt fuer einen ABS/DSC-Eingriffsindikator (noch nicht gefunden), da er aus der ABS-Domaene kommt.";
CM_ SG_ 134 SteeringAngle_related "ANALYSE-ERGAENZUNG (2026-09-14): die seit Wochen offene Frage 'warum bleibt dieses Signal schwach korreliert (r~0.56) trotz bestaetigt korrekter Bit-Position' ist sehr wahrscheinlich ein Messmethoden-Artefakt, kein reales schwaches Signal. Gegenprobe mit SPEARMAN statt Pearson gegen Steering_Wheel_Absolute_Angle@0x82 auf candump-2026-09-12_211833.log: r_spearman=0.987 (!) statt der bisher immer berichteten ~0.56 (Pearson, invariant unter linearer Reskalierung - daher kamen auch externe Formelquellen immer auf denselben Wert). Gebinnte Analyse (Rohwert gegen echten Winkel, 15 Bins -450..+449 Grad) zeigt eine klar monotone, aber STARK NICHTLINEARE Kurve: sehr flach/grobaufloesend um 0 Grad (Rohwert bewegt sich kaum zwischen -35 und +34 Grad, Bin-Standardabweichung dort 1475 vs. 150-220 in den Aussenbins), deutlich steiler weiter aussen (~8-12 Rohwert-Counts/Grad). Ein linearer Fit bewertet das zwangslaeufig als schwach (R²=0.03 in einer Stichprobe), obwohl die Rangfolge fast perfekt erhalten bleibt - derselbe Effekt wie beim ETC_ACT-Saettigungsfund vom 2026-09-12 (Pearson unterschaetzt saettigende/nichtlineare Zusammenhaenge systematisch), hier aber nie auf dieses schon 'erklaerte' Signal zurueckangewendet. Damit ist die Bit-Position definitiv bestaetigt richtig, die Charakterisierung als 'schwach' war falsch. Eine nutzbare nichtlineare Umrechnung (z.B. stueckweise linear oder Spline um die flache Mittelzone) ist NOCH NICHT gebaut - Skala/Offset bleiben bewusst (1,0), also Rohwert-Durchreichung.";
CM_ SG_ 1067 EngineRPM_related_3_maybe "Eigene Reverse-Engineering-Ergaenzung (2026-09-14), scripts/can_byte_search.py, Botschaft 0x42B war zuvor komplett leer in der DBC. Byte1-2 (16-bit unsigned BE) korreliert mit EngineRPM@0x202 mit Spearman r_detrended=0.62-0.79 in 4/5 Logs (fehlt in candump-2026-09-12_211833.log). Redundanzcheck gegen das bereits bekannte 'Drehzahl x2'-Duplikat EngineRPM_related_2@0x130 (Byte5-6): direkte Korrelation der beiden Rohwerte zueinander nur r=0.66 - VERWANDT, aber klar KEIN reines Duplikat (waere ~1.0), vermutlich eine andere drehzahlnahe Groesse (z.B. gefiltert/Ziel-/Governor-Drehzahl). Linearer Fit gegen echte EngineRPM nur R²=0.44 (RMSE~1300rpm) - zu ungenau fuer eine belastbare Kalibrierung, deshalb bewusst Rohwert-Durchreichung (1,0) statt einer vorgetaeuscht praezisen Formel. Einzelbyte (Byte1 allein) liefert denselben R², d.h. Byte2 traegt fast keine Zusatzinformation - moeglicherweise ist nur das hoehere Byte tatsaechlich befuellt.";
CM_ SG_ 121 YawRate_Corr "FORMEL KORRIGIERT (2026-09-14), Phase-4a-Rueckstands-Check gegen den vollen Anker-Satz aus scripts/can_byte_search.py. Die alte Formel (0.223437,-114.4) stammt unveraendert aus dem Original-Upstream-DBC (CM_-Kommentar '[deg/s] = [N-0x200]/0x200*114.4', nie in diesem Projekt verifiziert) und war falsch skaliert. Direkte Regression des ROHEN Byte3-4-Wertes (16-bit unsigned BE, vor jeder Formel) gegen YawRate_Raw@0x75 auf 2 Logs: candump-2026-09-14_081105 (0.1311,-67.07, R²=0.892), candump-2026-09-12_211833 (0.1349,-69.06, R²=0.919) - gemittelt auf (0.133,-68.1) gesetzt. Cross-log-Korrelationscheck (Spearman, ueber alle 4 Logs mit OBD-Traffic) zeigt r_detrended=0.94-1.00 - eines der staerksten Signale im gesamten Rueckstands-Check, klar kein Trend-Artefakt. Anders als die Geschwistersignale Longi_Acc_Corr/Lateral_Acc_Corr_maybe (beide nachweislich fehlerhaft, siehe dortige Notizen) ist YawRate_Corr also ein echtes, nur falsch kalibriertes Signal - nicht grundsaetzlich kaputt.";
CM_ SG_ 358 Clutch_Pedal_Position_related_2 "CROSS-LOG BESTAETIGT (2026-09-14, Phase-4a-Rueckstands-Check): die urspruengliche Ein-Log-Korrelation (r=0.9987, 2026-09-11) reproduziert sich ueber alle 4 Logs mit OBD-Traffic (r_detrended=0.9988-0.9992) - eines der zwei staerksten Signale im gesamten Rueckstands-Check (neben EngineRPM_related_2). Formel (1.25,0) bleibt unveraendert bestaetigt, keine Korrektur noetig - Kontrollregression auf einem frischen Log (candump-2026-09-14_081105) bestaetigt R²=0.9994 gegen Clutch_Pedal_Position_raw@0x130.";
CM_ SG_ 359 EngineLoad_or_Torque_pct_maybe "CROSS-LOG-LUECKE GESCHLOSSEN (2026-09-14, Phase-4a-Rueckstands-Check): bisher nur an einem einzigen Log kalibriert (siehe mx5_can_bus_status.md, 'Bekannte offene Punkte'). Jetzt gegen den vollen Anker-Satz aus scripts/can_byte_search.py an allen 4 Logs mit OBD-Traffic geprueft: korreliert konsistent mit APP_Accelerator_Pedal_Position (3/4 Logs, r_detrended=0.80-0.85) bzw. MAP_Manifold_absolute_pressure_sensor (1/4 Logs, r_detrended=0.89) - beides plausible Last-Proxys, passend zur bestehenden Interpretation als Motorlast/Drehmoment-Prozentwert. Keine Formelaenderung, aber die Kalibrierung gilt jetzt als mehrfach-log-bestaetigt statt nur einmalig.";
CM_ SG_ 512 EngineLoad_related_maybe "CROSS-LOG-BESTAETIGUNG (2026-09-14, Phase-4a-Rueckstands-Check UND unabhaengig per scripts/can_byte_search.py): korreliert konsistent mit APP_Accelerator_Pedal_Position (3/4 Logs, r_detrended=0.76-0.80) bzw. MAP (1/4 Logs, r_detrended=0.77) - selbe Last-Proxy-Domaene wie EngineLoad_or_Torque_pct_maybe@0x167. Redundanzcheck: direkte Korrelation gegen den unabhaengig im 09-14-Sweep gefundenen Kandidaten auf denselben 2 Bytes dieser Botschaft (0x200 Byte4-5, r=0.94) legt nahe, dass beide Bytebereiche (0-1 und 4-5) sehr aehnliche, aber nicht identische Information tragen - vermutlich zwei eng gekoppelte Lastgroessen, keine reine Duplizierung.";
CM_ BO_ 253 "GEPRUEFT, NICHT BESTAETIGT (2026-09-14, scripts/can_byte_search.py): Byte4-5 korreliert mit AFR_MZ (direkt aus CAN-Mode-22-Traffic dekodiert, siehe obd_from_can.py) mit Spearman r_detrended=0.72-0.83 in 4/5 Logs - aber der Rohwert deckt in jedem Log nur 2-3 verschiedene Ganzzahlen ab (z.B. 7680-7682), viel zu grobkoernig fuer ein echtes AFR-Signal. Linearer Fit dementsprechend schwach (R²=0.63-0.66) trotz brauchbarer Rangkorrelation. Vermutlich eine grob quantisierte Nebengroesse (Status/Stufe), die zufaellig mit dem langsam driftenden AFR mitlaeuft, kein eigenstaendiger AFR-Kanal. NICHT in die DBC uebernommen.";
CM_ BO_ 522 "GEPRUEFT, NICHT BESTAETIGT (2026-09-14, scripts/can_byte_search.py): Byte3-5 (mehrere Fensterungen) korreliert mit AFR_MZ mit Spearman r_detrended=0.62-0.73 in 4/5 Logs, aber linearer Fit nur R²=0.48-0.49 und Rohwertbereich unplausibel breit/asymmetrisch (bis zu -32768..255 je nach Fensterung) - deutet auf haeufige Vorzeichen-/Wrap-Artefakte statt eines sauberen Signals hin. NICHT in die DBC uebernommen, zu unsicher.";
CM_ BO_ 579 "GEPRUEFT, VERWORFEN (2026-09-14, scripts/can_byte_search.py): 0x243, im ersten Sweep (nur candump-2026-09-14_173057.log) zeigte Byte1-3 eine sehr starke Korrelation mit WheelSpeed_1 (r_detrended bis 0.97) - direkt an zwei weiteren Logs (candump-2026-09-12_211833, candump-2026-09-14_081105) nachgeprueft: dort r=-0.06 bis -0.07, praktisch keine Korrelation. Klassisches Kurz-Log-Trendartefakt (173057 ist mit ~3min der kuerzeste der 5 Logs) statt eines echten Signals. NICHT in die DBC uebernommen. Gleiche Schlussfolgerung gilt fuer die begleitenden Funde auf 0x488/0x211-Byte6-7/0x245 in demselben Sweep-Lauf, ebenfalls verworfen.";
CM_ SG_ 80 StarterInterLockSW "HOCHGESTUFT (2026-09-15): die 09-11-Vermutung 'Byte3-Korrelation stammt vermutlich nur vom StarterInterLockSW-Bit selbst, kein Zusatzsignal' wird durch externe Quelle (github.com/gitgc/mx5-miata-nd2-obd-can) widerlegt/praezisiert: Byte3 als GANZES ist dort ein eigenstaendiges binaeres Kupplungs-Pedal-Flag (rohwert 1=nicht getreten, 2=getreten). Cross-log an allen 3 verfuegbaren Logs bestaetigt: r=0.86-0.90 gegen Clutch_Pedal_Position_raw@0x130 (Werteverteilung durchgehend nur {1,2}). Kein eigenes SG_ ergaenzt (ueberlappt mit StarterInterLockSW@Bit25, cantools wuerde die Botschaft sonst nicht mehr dekodieren) - Formel/Fund hier dokumentiert, analog zum BrakePressure/Bremspedal-%-Fall.";
CM_ SG_ 576 SteeringTorque_maybe "Eigene Reverse-Engineering-Ergaenzung (2026-09-15), Ausgangspunkt war commaai/opendbc mazda_2017.dbc, wo Byte0 dieser Botschaft als STEER_TORQUE_SENSOR gefuehrt wird (Botschaft dort: STEER_TORQUE, Sender EPAS - passt zu unserem HS_EPAS). Ueberlappt bitweise KEIN bekanntes Signal von uns. Eigene Pruefung ueber 5 Logs: der Rohwert minus 127 liegt im Median sowohl im Stand als auch bei Geradeausfahrt >40 km/h exakt bei 0 (Offset -127 damit bestaetigt), Wertebereich etwa -77..+127. Korrelation gegen Steering_Wheel_Absolute_Angle@0x82 ist STARK geschwindigkeitsabhaengig: ueber das ganze Log nur r=0.23-0.52, gefiltert auf >40 km/h dagegen r=0.78-0.86 in allen 5 Logs (gegen Lateral_Acc_Raw@0x75 aehnlich, r=0.81-0.88). Genau dieses Muster erwartet man bei einem LENKMOMENT und nicht bei einem skalierten Winkel: bei Parkiergeschwindigkeit dominiert der Reifenscrub (viel Moment, wenig Winkel), bei Fahrgeschwindigkeit das geschwindigkeitsabhaengige Rueckstellmoment. Zwei weitere Indizien: die Streuung ist im Stand mehr als doppelt so gross wie bei Geradeausfahrt (14.1 vs 6.0), und das Signal LAEUFT dem Lenkwinkel VORAUS (Kreuzkorrelation steigt monoton von r=0.86 bei Lag 0 auf r=0.88 bei -0.4s) - ein Fahrer-Eingangsmoment geht der Winkelaenderung voraus, ein skalierter Winkel haette sein Maximum bei Lag 0. EINSCHRAENKUNG: nach Herausrechnen des Lenkwinkels bleibt nur r=0.14 Restkorrelation mit der Querbeschleunigung - das Signal ist also weitgehend durch den Winkel erklaerbar und KEINE unabhaengige Querkraftmessung. Physikalische Einheit unbekannt und nicht kalibrierbar, weil es im Fahrzeug keinen Referenz-Momentenkanal gibt (weder OBD noch CAN) - Skala bewusst als (1,-127) Rohwert-Durchreichung belassen. Deshalb _maybe.";
CM_ SG_ 134 SteeringAngle_EPAS_Abs_maybe "Eigene Reverse-Engineering-Ergaenzung (2026-09-15). ERSETZT das fruehere SteeringAngle_related_3 (war 39|16, also Byte4-5) - das sass auf den FALSCHEN Bits. Ausgangspunkt war commaai/opendbc mazda_2017.dbc, wo an dieser Stelle STEER_ANGLE_ROUGH definiert ist (26|11). Eigene Pruefung: gegen Steering_Wheel_Absolute_Angle@0x82 zunaechst nur R²=0.56 - GLEICHE URSACHE wie beim Schwestersignal SteeringAngle_EPAS: die Frames mit gesetztem SteeringAngle_EPAS_Invalid (0.08-0.54%) tragen hier 2047 statt eines gueltigen Werts und kippen die Statistik. Nach Verwerfen dieser Frames: R²=0.9997-0.9999, RMSE 0.72-1.07 Grad ueber 5 Logs, Skala 1.6000-1.6058 und Offset -1599..-1605 - also durchgehend (1.6,-1600). Das ist exakt dieselbe Formelfamilie wie der feine Kanal (0.1,-1600), nur um Faktor 16 groeber: eine grob aufgeloeste Zweituebertragung desselben Winkels, KEINE eigenstaendige Groesse. Praktischer Nutzen daher gering (SteeringAngle_EPAS ist mit 15 Bit besser), aber die Botschaft ist damit korrekt beschrieben. WICHTIG: beim Dekodieren immer Frames mit SteeringAngle_EPAS_Invalid=1 verwerfen. Byte4-5, wo frueher SteeringAngle_related_3 stand, bleibt UNIDENTIFIZIERT: Spearman 0.79-0.87 gegen den echten Winkel, aber R²=0.003-0.08 UND anders als die beiden Winkelkanaele NICHT durch das Invalid-Flag erklaerbar (R² bleibt nach Filtern unveraendert). Die fruehere Charakterisierung 'zweites, nichtlineares Lenkwinkelsignal' ist damit nicht belegt. AUFLOESUNG 2026-09-26 ERWEITERT (11 -> 15 Bit): Byte5 obere Nibble (Bits 47-44) sind die 4 Feinbits desselben Winkels, also 0,1 statt 1,6 Grad je LSB (26|15, raw*0,1-1600). Frueherer Name SteeringAngle_EPAS_Coarse. Nachweis gegen den absoluten SSU-Winkel (0x082): Median-Versatz 0,0-0,65 Grad in vier Logs (SteeringAngle_EPAS auf 0x086 derselben Botschaft: -4,5..+10 Grad, driftet pro Log und braucht die Nullpunktkorrektur), 90%-Perzentil der Restabweichung 0,75-2,05 Grad (Interpolationsschaetzung, keine Sync-Abtastung). Der Kanal ist also eine zweite, NULLPUNKTSTABILE Winkelspur - fuer CAN-Logs ohne 0x082 als Ersatz brauchbar. Byte5 untere Bits (Werte 0-3 in Bit1-0, Bit3=1, Bit2=0) ungeklaert.";
CM_ SG_ 253 FuelCut "Eigene Reverse-Engineering-Ergaenzung (2026-09-15), scripts/can_find_native_counterpart.py. Byte5 Bit1 (Rohwert von Byte4-5 springt nur zwischen 0x1E00 und 0x1E02, also ein einzelnes Bit). BESTAETIGT ueber zwei unabhaengige Fahrten gegen den Standard-Mode-1-PID 0x44 (commanded equivalence ratio): wenn das Soll-Lambda > 1,9 ist - also der Kraftstoff abgeschaltet -, ist dieses Bit in 99,4% (Hinfahrt) bzw. 98,8% (Rueckfahrt) der Faelle gesetzt. Umgekehrt ist es zu 86-89% von Lambda>1,9 begleitet; die Abweichung erklaert sich aus der nur ~1,8 Hz schnellen OBD-Abtastung gegen ein Bit, das mit Botschaftsrate wechselt. Gegen die Fahrzustaende geprueft: gesetzt zu 96-98% nur bei geschlossenem Gaspedal UND Drehzahl ueber 1200 1/min, ausserhalb dieser Bedingung nur zu 0,4%. Es deckt rund 38% aller Schubphasen ab - passend dazu, dass die Schubabschaltung erst oberhalb einer Drehzahlschwelle greift und vor dem Leerlauf wieder aufmacht. WICHTIG fuer das Fahrleistungsmodell: das Schleppmoment unterscheidet sich grundlegend zwischen abgeschalteter und weiterlaufender Einspritzung, und dieses Bit liefert den Zustand mit voller Botschaftsrate statt mit 1-2 Hz OBD-Polling (siehe scripts/engine_braking_analysis.py). ACHTUNG bei der Interpretation des Fundwegs: der Kandidat tauchte in der Suche nach einem nativen LAMBDA-Gegenstueck auf (Transfer-R2=0,88) - ein Lambda ist es NICHT, der Rohwert kennt nur zwei Zustaende. Die Korrelation kam daher, dass die Varianz des Soll-Lambdas von den Schubphasen dominiert wird.";
CM_ SG_ 359 ActualEnginePercentTorque "BESTAETIGT und neu kalibriert (2026-09-15), vorher EngineLoad_or_Torque_pct_maybe. Uebertragungstest ueber zwei unabhaengige Fahrten gegen den Standard-Mode-1-PID 0x62 (Actual engine - percent torque, SAE J1979): R2=0,967 bzw. 0,965 je Fahrt, und - entscheidend - die auf der einen Fahrt gefittete Kalibrierung sagt die andere mit R2=0,962 vorher. Ein Trend-Artefakt haette dort ein negatives R2 geliefert. Damit ist die Zuordnung nicht mehr blosse Vermutung. Kalibrierung gemeinsam ueber beide Fahrten gefittet (n=4410): 3,0242*raw-177,849, R2=0,962, RMSE=4,07 Prozentpunkte. Ersetzt die alte Formel (3,17,-185,3), die aus einem einzelnen Log stammte - die neue ist auf BEIDEN Fahrten besser (RMSE 4,07 gegen 4,70). Einschraenkung: die Steigung schwankt zwischen den Fahrten um 3,4% (2,971 bis 3,073), die Formel ist also nicht praeziser als etwa 4 Prozentpunkte.";
CM_ SG_ 159 ReverseGear_IC "Rueckwaertsgang aus Sicht des Kombiinstruments (Byte0 Bit0), Spiegel des PCM-Rueckfahrschalters 0x165 Bit 24/25 (+0,03 s), 42/42 Rueckwaerts-Episoden aller Logs, ~0,5 s vor 0x445 ReverseGear. 5 Hz. Fuer die Live-Ganganzeige im Dash (Test C2, 2026-09-26).";
CM_ SG_ 159 Reverse_Flag_maybe "Nie gesetzt (alle Logs). Der Rueckwaertsgang steht in 0x09F Bit 0 (DBC-Bitnummer 0 = Byte0 LSB), nicht Bit 7: 42/42 Rueckwaerts-Episoden, 0,03 s nach dem PCM-Rueckfahrschalter (0x165 Bit 24). Vermutlich Bitreihenfolge in der Quell-DBC vertauscht. Eigene Ergaenzung 2026-09-26 (Test C2).";
CM_ SG_ 253 MT_Gear_Actual "Gang aus Drehzahl/Geschwindigkeit (0 = kein Gang erkannt, auch bei Stillstand und im Rueckwaertsgang). Wert 7 ist KEIN Rueckwaertsgang: er erscheint in jedem Log fuer ~2 s direkt nach Zuendung EIN (Initialisierungswert, 28 Logs), nie waehrend ReverseGear=1. Die fruehere Deutung 7 = Rueckwaerts mit eingekuppelter Kupplung (2026-09-12) ist damit widerlegt (Test C2, 2026-09-26).";
CM_ SG_ 357 CC_Mode_Related2 "Byte3 von 0x165 ist kein reines Tempomat-Feld: Bit 24 und Bit 25 (Byte3 0x03) = Rueckfahrschalter des PCM, 42/42 Rueckwaerts-Episoden aller Logs, 0,56 s vor 0x445 ReverseGear (Test C2, 2026-09-26). Die oberen Bits wechseln mit dem Motor-/Kupplungszustand (0xC0 Motor aus, 0x70/0x74 im Betrieb). Nicht als eigenes Signal eingetragen, weil es CC_Mode_Related2 ueberlappen wuerde.";
CM_ SG_ 1093 ReverseGear "BESTAETIGT (2026-09-26): bei ReverseGear=1 ist das Vorzeichen Gierrate/Lenkwinkel in 99,7 % der Rangierproben umgekehrt (n=1195, |Lenkwinkel|>60 deg, |Gierrate|>2 deg/s), bei ReverseGear=0 nur in 0,4 % (n=13930). Eigene Reverse-Engineering-Ergaenzung (2026-09-26), scripts/can_natural_events.py (Ereignis 'reverse': Rueckwaertsfahrt erkannt am umgekehrten Vorzeichen Gierrate/Lenkwinkel bei 1-12 km/h). Byte0 Bit7 von 0x445 (HS_IC_PSM_MZ, Einparkhilfe-Botschaft, 5 Hz): gesetzt in 20 Logs genau in den Rangierphasen (Episoden 2-17 s, bis 10 km/h), in 17 von 18 Logs mit erkannter Rueckwaertsfahrt ereignisspezifisch (innen 50 %, Kontrolle Vorwaertsrangieren 0,9 %). MT_Gear_Actual zeigt waehrend dieser Phasen 0 (nicht 7) - das erklaert, warum der Rueckwaertsgang dort nie gefunden wurde; Reverse_Flag_maybe (0x9F) ist in keinem Log je gesetzt. Byte2 (PSM_State_maybe) wechselt gleichzeitig von 6 auf 7. Keine Abstandswerte in der Botschaft (vermutlich keine Parksensoren verbaut, die Botschaft traegt nur den Rueckwaertsgang-Status). Fahrzeugtest C2 (2026-09-26, candump-2026-09-26_120235, 64,8-97,5 s, Zuendung ein, Motor aus): drei Mal eingelegt, drei Episoden, bestaetigt. Quellenkette (alle 42 Rueckwaerts-Episoden aller Logs 1:1): PCM 0x165 Bit 24+25 (Rueckfahrschalter, zuerst) -> IC 0x09F Bit 0 (+0,03 s) -> IC 0x477 Bit 17 (+0,17 s, Bit 16 invers) -> 0x445 Bit 7 (+0,56 s Median beim Einlegen, beim Auslegen gleichzeitig). Fuer schnelle Erkennung 0x165 Bit 24 oder 0x09F Bit 0 nehmen. Im Rueckwaertsgang: MT_Gear_Select=1 (InGear), MT_Gear_Position=19 wie N/1st, MT_Gear_Actual=0.";
CM_ SG_ 1093 PSM_State_maybe "Byte2 von 0x445: 6 im Betrieb, 7 mit eingelegtem Rueckwaertsgang (Bit0 = Kopie von ReverseGear), 0 vor/nach dem Betrieb. Eigene Ergaenzung 2026-09-26.";
CM_ SG_ 1271 ColdEngine_Indicator "Eigene Reverse-Engineering-Ergaenzung (2026-09-26), scripts/can_natural_events.py (Ereignis 'cold'). Byte0 von 0x4F7 (HS_IC) ist 48 (Bits 4+5, Wert 3) bei kaltem Motor, sonst 0. Schaltet in ALLEN 21 beobachteten Uebergaengen (21 Logs) exakt bei CoolantTemp = 55,0 Grad ab und nach Zuendung EIN bei kaltem Motor (12-53 Grad) ein. Vermutlich die blaue Kaltlauf-Kontrollleuchte im Kombiinstrument (Fahrzeugtest: Leuchte beim Kaltstart beobachten).";
CM_ SG_ 359 BrakeSwitch_PCM "Eigene Reverse-Engineering-Ergaenzung (2026-09-26), scripts/can_natural_events.py (Ereignis 'brake_light', 28/28 Logs). Byte2 Bit3 von 0x167: P(gesetzt | Bremsdruck > 2 bar) = 1,000 (n=261.346), P(gesetzt | < 2 bar) = 0,018 (leichtes Antippen ohne Druckaufbau). Bremslichtschalter, wie ihn das Motorsteuergeraet sieht. BrakeSwitch_PCM_Inv (Bit 2) ist das invertierte Redundanzbit (0,000 / 0,982), BrakeSwitch_PCM_2 (Bit 0) eine zweite Kopie (1,000 / 0,018). Dieselbe Bedingung setzt auch Bits in 0x165 (CC_Mode_Related), dort zusaetzlich bei Leerlauf/Kupplung - vermutlich Tempomat-Abschaltbedingungen.";
CM_ SG_ 357 CC_Mode_Related "Tempomat-Zustand (2026-09-26, candump 2026-09-26_184447 + 2026-09-19_163755, scripts/can_cruise_flag_check.py). Rohwert 149 = Tempomat regelt bzw. uebersteuert (bleibt beim Gasgeben an), 141 = aus/bereit, 302 = Bremse/Stand, 129/174 selten. Jedes 149-Segment beginnt genau beim Setzen (CC_SetSpeed wechselt) und endet beim Abbrechen. Die VAL-Tabelle 0=OFF/1=ON ist nie aufgetreten.";
CM_ SG_ 357 CC_SetSpeed "Tempomat-Soll in Tacho-km/h (~4 % ueber der echten Geschwindigkeit), bleibt nach dem Abbrechen gespeichert - sagt also NICHT, ob der Tempomat gerade regelt (dafuer CC_Mode_Related == 149). Spiegelt 0x21F Byte0-1 (big-endian, 0,005*raw-0,5 = echte km/h im Setzmoment, opendbc CRZ_SPEED: 51,5 und 41,7 km/h gegen Soll 55 bzw. 45).";
CM_ SG_ 359 BrakeSwitch_PCM_Inv "Invertierte Kopie von BrakeSwitch_PCM (Byte2 Bit2). Eigene Ergaenzung 2026-09-26.";
CM_ SG_ 359 BrakeSwitch_PCM_2 "Zweite Kopie von BrakeSwitch_PCM (Byte2 Bit0). Eigene Ergaenzung 2026-09-26.";
CM_ SG_ 1086 AnyDoorOpen "Eigene Reverse-Engineering-Ergaenzung (2026-09-26), scripts/can_natural_events.py (Ereignis 'door'). Byte3 Bit6: P(gesetzt | DoorLeft oder DoorRight offen) = 1,000 (n=2.110), sonst 0,0002. Sammelmeldung 'eine Tuer offen' (Kontrollleuchte).";
CM_ SG_ 1086 BrakeLamp "Eigene Reverse-Engineering-Ergaenzung (2026-09-26). Byte6 Bit5: P(gesetzt | Bremsdruck > 2 bar) = 1,000, sonst 0,028 - Bremsleuchten-Status des Karosseriesteuergeraets (BCM). Nur in Logs mit 0x43E-Verkehr (n=10.472).";
CM_ SG_ 138 DCDC_Voltage "Eigene Reverse-Engineering-Ergaenzung (2026-09-26), scripts/can_anchor_sweep.py (neuer Anker Batteriespannung = Mode-1-PID 0x42, von tpms_poller.py alle 10 s gepollt). 10 Bit ab Startbit 19 (Byte2 Bit3..0 + Byte3 Bit7..2) big-endian, 0,02 V/LSB ohne Offset: gegen PID 0x42 in 16 Logs r=0,9986, Fit U=0,0199*raw+0,08 V (n=1664). Das oberste Bit (10,24 V) ist bei Bordnetzspannung immer gesetzt und das zweite (5,12 V) immer 0 - genau das erwartete Bitmuster. Bereich 8,1 V (Anlassen) bis 14,8 V. 100-Hz-Botschaft, also Bordnetzspannung mit voller Rate statt 0,1 Hz OBD. Physikalisch bestaetigt, trotzdem ohne Messgeraet-Referenz; Fahrzeugtest: Multimeter an der Batterie gegen Anzeige.";
CM_ SG_ 1087 BCM_SupplyVoltage "Eigene Reverse-Engineering-Ergaenzung (2026-09-26). Gleiche Bitlage wie DCDC_Voltage (19|10), aber 0,016 V/LSB: r=0,998 gegen PID 0x42 (RMSE 0,042 V nach Offset), gegen DCDC_Voltage r=0,997, Steigung 0,99, konstant 0,68 V NIEDRIGER ueber den ganzen Bereich 11-15 V (vermutlich Messpunkt hinter einer Verpolschutzdiode im BCM). Rohwert*0,016 ist die Spannung, wie das BCM sie misst - fuer die Batteriespannung 0,68 V addieren oder DCDC_Voltage nehmen. 20 Hz.";
CM_ SG_ 138 iELOOP_CapVoltage_maybe "Eigene Reverse-Engineering-Ergaenzung (2026-09-26). 10 Bit ab Startbit 13 (Byte1 Bit5..0 + Byte2 Bit7..4), gleiches Format wie DCDC_Voltage, Skala 0,04 V/LSB angenommen (nicht referenzgemessen): Werte 13,8-24,6 V, genau der Arbeitsbereich des i-ELOOP-Doppelschichtkondensators (max. 25 V). Verhalten ueber alle Logs mit 0x4DB: in der Rekuperation (DCDC_State_maybe=4) steigt der Wert im Mittel um +0,43 V/s (64 % der Samples steigend), im Normalbetrieb (State 8) faellt er (Median -0,2 V/s, Entladung ins Bordnetz), bei Motor aus bleibt er konstant. iELOOP_CapVoltage_2_maybe (53|10) ist eine identische Kopie. Skala unsicher: 0,02 V/LSB gaebe 6,9-12,3 V, was fuer einen 25-V-Kondensator unplausibel ist. Fahrzeugtest: Kondensatorspannung ist nicht zugaenglich; Plausibilitaet ueber den Ladezustand bei laengerem Schub pruefen (sollte bei ~25 V saettigen).";
CM_ SG_ 138 DCDC_Voltage_2_maybe "Zweite Bordnetzspannung (25|10, 0,02 V/LSB), deckungsgleich mit DCDC_Voltage bis auf wenige Zaehler (r=0,99-1,00) - vermutlich Ein- und Ausgangsseite des Wandlers. Eigene Ergaenzung 2026-09-26.";
CM_ SG_ 138 DCDC_Field45_raw_maybe "Unbekanntes 8-Bit-Feld (45|8, Byte5 Bit5..0 + Byte6 Bit7..6; die beiden folgenden Bits gehoeren schon zu iELOOP_CapVoltage_2_maybe, deren Bitmuster exakt dem von 13|10 entspricht): 0 bei stehendem Motor, bis 255 im Betrieb (erste Auswertung als 10-Bit-Feld 1-1021), r=0,65-0,89 gegen die Bordnetzspannung, im Rekuperationszustand niedriger (500 gegen 615). Keine Korrelation mit der Entladerate des Kondensators (r=-0,03). Vermutlich Tastverhaeltnis oder Strom des Wandlers bzw. Generator-Sollwert. Fahrzeugtest: Stromzange an der Batterie/am Generator, grosse Verbraucher (Heckscheibenheizung, Licht, Luefter) schalten. Eigene Ergaenzung 2026-09-26.";
CM_ SG_ 138 DCDC_Active_maybe "Byte0 Bit6: 0 bei stehendem Motor, 1 wenn der Motor laeuft (P=0,999 gegen Drehzahl>400). Eigene Ergaenzung 2026-09-26.";
CM_ SG_ 1056 FuelConsumption_Counter "KORREKTUR 26.09. (spaeter): der Zaehler ist NUR Byte2 (8 Bit); Byte3 ist in allen Logs konstant 51/52 und gehoert nicht dazu. Die unten genannten Zahlen beziehen sich auf Byte2-3 als 16 Bit - fuer Byte2 allein durch 256 teilen: ~7,0 Schritte je Gramm, ~0,142 g bzw. ~0,19 ml je Schritt, Leerlauf ~1,2 Schritte/s. Wegen der groben Aufloesung den Strom ueber ein Fenster von einigen Sekunden bilden (build_datalake: 2 s). Eigene Reverse-Engineering-Ergaenzung (2026-09-26), gefunden mit einer Suche nach Zaehlern mit VARIABLER Rate (Zuwachs je 2-s-Fenster gegen abgeleitete Groessen; alle frueheren Sweeps haben monotone Reihen verworfen). Byte2-3 big-endian, umlaufender 16-Bit-Zaehler der eingespritzten Kraftstoffmenge: Zuwachsrate gegen Drehmoment*Drehzahl r=0,992 (min 0,988, 5 Logs), gegen Kraftstoffstrom aus OBD-Luftmasse/(14,7*Soll-Lambda) r=0,99-0,999 in 20 von 24 Logs. Kalibrierung: 1750-1850 Zaehlschritte je Gramm (Median ~1800, also ~0,56 mg bzw. ~0,75 uL je Schritt, Unsicherheit ~10 % aus der MAF-Schaetzung). Leerlauf ~300 Schritte/s = ~0,8 l/h, im Schub (FuelCut) ~25 Schritte/s. Kraftstoffstrom = Zuwachs/dt; Umlauf bei 65536 beachten. In 3 Logs (15.09. 084853: 80, 17.09. 133436: 6, 12.09. 211833: 4) einzelne Spruenge >5000 Schritte - als ungueltig verwerfen. Tankfuellstand als Gegenprobe zu verrauscht (Tanken zwischen Logs, Schwappen), ergibt grob 0,7-1,0 uL/Schritt. Fahrzeugtest fuer die exakte Einheit: Bordcomputer-Durchschnittsverbrauch zuruecksetzen, Fahrt, angezeigten Wert gegen Zaehlerstand/Strecke vergleichen; oder Volltanken-Methode. KALIBRIERT 2026-09-26 abends gegen den Bordcomputer (Fahrzeugtest C3): nach dem Zuruecksetzen des Durchschnittsverbrauchs (AvgFuelConsumption, 0x4F3) folgt die Anzeige dem Zaehler mit 5024 Schritten je Liter (candump-2026-09-26_142216, 40 Anzeige-Updates, Rest 2,6 ml) bzw. 5026 (unabhaengig im Folgelog _154000) - also 0,199 ml je Schritt in der Einheit des Kombiinstruments, ~4,5 % mehr als die MAF/Lambda-Schaetzung. Strecke dabei aus Travel_distance_related (0,1992 m/Schritt, ODO-kalibriert). Absolute Wahrheit (getankte Liter) weiter offen: Volltank-Methode. ABSOLUT 2026-09-26 (Voll-bis-Voll): zwischen den Volltankungen 16.09. (Reset bei ODO 169941,87) und 26.09. (Reset bei 170387,84, 445,97 km) zeigte der Bordcomputer 7,42 l/100km = 33,09 l, getankt wurden 34,4 l (Rechnung) - der Bordcomputer zaehlt 4,0 % zu wenig. Echte Einheit also 4834 Schritte je Liter = 0,207 ml je Schritt (Unsicherheit v. a. Fuellstand beim Abschalten der Zapfpistole, ~1-1,5 %). NEU KALIBRIERT 2026-10-26: lueckenlose Voll-bis-Voll-Kette 16.09.-26.10. (5 Tankstopps, 144,45 l getankt; 04.10. aus Betrag/Literpreis) 4985 Schritte je Liter = 0,201 ml je Schritt; Einzelintervalle 4834-5203, Rest je Intervall <= 1,0 l (Fuellstand beim Abschalten), Unsicherheit der Kette ~1 %.";
CM_ SG_ 1056 AmbientTemp "KORRIGIERT 2026-09-26. Die bisherige Definition 55|16 signed (0,0025, +32) lieferte in ALLEN 29 Logs konstant 25,7-25,9 Grad (auch nachts um 23:34) - der Rohwert Byte6-7 schwankt nur zwischen 63024 und 63090, Byte6 ist konstant 246. Die am 2026-09-15 berichtete Spanne 3,8-25,9 Grad kam nur vom Initialisierungswert 0xD400 (54272) in den ersten Frames. Der Wert steckt in Byte7 allein und verhaelt sich wie ein Aussentemperaturfuehler: morgens niedrig, nachmittags hoch, nachts wieder niedriger; nach kurzem Abstellen erhoeht (Stauwaerme) und waehrend der Fahrt fallend (z.B. 17.09. 084511: 114->78 roh). KALIBRIERUNG 2026-09-26 nachts: T = raw/4 (0,25 Grad/LSB, Offset 0) - passt zu sechs Morgenstarts gegen die 15-min-Temperatur von Open-Meteo (RMSE 0,5 K), zum Garagenstart 09-14_163711 (raw 103 = 25,8 Grad bei 24-28 Grad Garage) und zur Anzeige 20 Grad bei raw 73-81; die aeltere Formel 0,3477*raw-6,3 (unten) war zu steil (raw 103 -> 29,7 Grad) und ist ersetzt. Die aeltere Herleitung: Kalibrierung vorlaeufig gegen die Ansauglufttemperatur bei 10 Kaltstarts (Kuehlwasser-IAT <= 4 K, also Motor im Temperaturgleichgewicht): T = 0,3477*Byte7 - 6,3 Grad, r=0,987, RMSE 1,2 K. Skala unsicher (0,3-0,4 fittet fast gleich gut). OBD-Referenz gibt es nicht: PID 0x46 wird vom Fahrzeug nicht unterstuetzt (probe-20260916-081915.csv). Fahrzeugtest: Aussentemperatur-Anzeige im Kombiinstrument bei zwei moeglichst verschiedenen Temperaturen notieren. 2026-09-26 abends: Nutzer sah in der letzten Fahrt (candump-2026-09-26_184447, Byte7 73-81, Wetterstation 18,5 Grad) 20 Grad - passt zur Formel (19,3-22,1 Grad) UND zu 0,25*raw (18,3-20,3); ein Ankerpunkt entscheidet die Steigung nicht. Ueber 89 Minutenfenster bei > 90 km/h gegen die Stundentemperatur von Open-Meteo: T = 0,215*raw + 0,9 (r = 0,85, RMSE 1,6 K, Regressionsverduennung: wahre Steigung 0,22-0,30). Formel unveraendert; Zweitpunkt bei deutlich anderer Temperatur (< 10 Grad) fehlt.";
CM_ SG_ 1056 Travel_distance_related "BESTAETIGT 2026-09-26 als Wegzaehler: Byte1 ist ein umlaufender 8-Bit-Zaehler, dessen Zuwachs je 5-s-Fenster der integrierten VehicleSpeed-Strecke mit r=1,000 folgt (3 Logs), 0,209 m je Schritt in allen drei Logs gleich (0,209/0,209/0,210). Vermutlich Radimpulse (ca. 9 je Radumdrehung bei 1,9 m Abrollumfang). Umlauf bei 256 beachten; Skala haengt an der VehicleSpeed-Kalibrierung. KORREKTUR 2026-09-26 abends: gegen die exakten Kilometerstand-Inkremente von C001_ODO (0x40A) in 5 Logs vom 26.09. sind es 0,1992 m je Schritt (0,1992/0,1992/0,1992/0,1992/0,1993) - die 0,209 stammten aus dem VehicleSpeed-Integral, und VehicleSpeed liegt ~5 % ueber der ODO-Strecke (GPS: VehicleSpeed ~3 % zu hoch). Skala auf 0,1992 umgestellt.";
CM_ SG_ 1114 BattSensor_Voltage_maybe "Eigene Reverse-Engineering-Ergaenzung (2026-09-26). 0x45A traegt offenbar die Werte des Batteriesensors (i-stop-Fahrzeuge haben einen Sensor am Minuspol). 13 Bit ab Startbit 45, 1/512 V je LSB: gegen PID 0x42 r=0,966, Fit U=0,00196*raw+0,19 V, RMSE 0,17 V (schlechter als DCDC_Voltage, vermutlich anderer Messpunkt/Filter). Beim Kaltstart (candump-2026-09-14_081105 t=240 s) sackt der Wert waehrend des Anlassens von 11,78 auf 9,65 V ab und erholt sich danach - genau das Verhalten der Batterieklemmenspannung. Fahrzeugtest: Multimeter an der Batterie.";
CM_ SG_ 1114 BattSensor_Current_raw_maybe "Eigene Ergaenzung (2026-09-26). 12 Bit (Byte0 Bit3..0 + Byte1). Motor aus (Zuendung an) ~3665, Motor laeuft ~3720-3740, beim Anlassen bis ~2880-2980 in allen Logs: sieht aus wie der Batteriestrom mit Nullpunkt um ~3690 (Entladung negativ). Skala unbekannt (bei 0,25 A/LSB waere der Anlassstrom ~200 A). Fahrzeugtest: Stromzange am Batteriekabel, Verbraucher (Licht, Heckscheibenheizung, Luefter) schalten, Anlassstrom messen.";
CM_ SG_ 1114 BattSensor_Temp_maybe "Eigene Ergaenzung (2026-09-26). Byte3: bei 10 Kaltstarts gegen die Ansauglufttemperatur r=0,966, raw-40 liegt im Mittel 1,5 K darueber (RMSE 2,1 K); innerhalb einer Fahrt fast konstant (z.B. 56->57), wie es fuer die grosse Waermekapazitaet einer Batterie zu erwarten ist. 255 = ungueltig (erste Frames). Vermutlich Batterietemperatur. Fahrzeugtest: Thermometer an der Batterie nach laengerem Stand.";
CM_ SG_ 1114 BattSensor_Byte4_maybe "Eigene Ergaenzung (2026-09-26). Byte4: 55-76, bei Kaltstart r=0,982 gegen die Ansauglufttemperatur, steigt aber waehrend einer Fahrt (z.B. 59->70 in 48 min), anders als Byte3. Entweder eine zweite Temperatur (Sensorelektronik im Motorraum) oder der Ladezustand (SOC %). Fahrzeugtest: nach langer Standzeit vs. nach Autobahnfahrt vergleichen; Batterie mit Ladegeraet laden und Verlauf beobachten.";
CM_ SG_ 1114 BattSensor_Byte7_maybe "Eigene Ergaenzung (2026-09-26). Byte7: 134-158, sinkt waehrend einer Fahrt langsam (158->154), von Log zu Log verschieden, nicht temperaturkorreliert. Kandidaten: Ladezustand, Alterungszustand (SOH), Innenwiderstand. 255 = ungueltig.";
CM_ SG_ 117 RCM_Temperature_maybe "Eigene Reverse-Engineering-Ergaenzung (2026-09-26), scripts/can_anchor_sweep.py (Byte6 steigt in 27 von 29 Logs monoton ueber die Fahrt, Spearman 0,98 gegen die Zeit). Bei 10 Kaltstarts (Motor im Temperaturgleichgewicht) gegen die Ansauglufttemperatur: Steigung 0,89 K/LSB, r=0,980, raw-103 ohne mittlere Abweichung (RMSE 1,8 K). Steigt waehrend einer Fahrt um 10-24 K (z.B. 117->141) - Eigenerwaermung bzw. Innenraum/Tunnel. Vermutlich Innentemperatur des Airbag-/Inertialsensor-Steuergeraets (RCM), die fuer die Temperaturkompensation der Drehraten-/Beschleunigungssensoren gebraucht wird. Offset -103 ist eine Anpassung, nicht bewiesen (-100 oder -40 mit anderer Skala moeglich). Fahrzeugtest: nach Standzeit ueber Nacht Aussentemperatur vs. Wert.";
CM_ SG_ 253 EngineRunning "Eigene Reverse-Engineering-Ergaenzung (2026-09-26), scripts/can_natural_events.py (Ereignisse engine_start/engine_stop). Byte0 Bit0: P(1 | Drehzahl > 400) = 1,000, P(1 | i-stop-Motorstopp) = 0,03 ueber 97 automatische Stopps in allen Logs; faellt ~0,8 s nach Beginn des Drehzahlabfalls. EngineRunning_3 (Bit6, gleiche Botschaft) und EngineRunning_2 (0x09F Bit16) verhalten sich identisch.";
CM_ SG_ 253 CruiseActive_Inv "Eigene Ergaenzung (2026-09-26, Auswertung der Tempomat-Tests vom selben Tag): Byte7 Bit5 (DBC-Bit 61) ist 0, solange der Tempomat regelt (CC_Mode_Related@0x165 == 149), sonst 1. 50 Hz statt der langsameren 0x165. Nach den Tempomatfahrten vom 26.09.: 55 von 55 Segmenten (>= 10 s) schalten beim Start und beim Ende innerhalb von 0,5 s (im Beispiel 20 ms) mit dem 149-Wechsel; ueber alle 33 Logs seit 11.09. 356.029 Frames mit 149 und Flag 0 gegen 61 mit 149 und Flag 1 (0,02 %), umgekehrt 9.395 Frames Flag 0 ohne 149 (davon 8.638 mit 141, Ursache nicht einzeln geprueft, vermutlich Zeitversatz an den Segmentgrenzen). Auch bei Uebersteuern durch Gas bleibt es 0.";
CM_ SG_ 157 CRU_CON_SW1 "Lenkrad-Tempomattasten, Eigene Ergaenzung 2026-09-26 (Byte0 einzeln, 10 Hz, jeder Druck ein 0,1-0,2-s-Puls; Byte2 spiegelt die Bits invertiert, Byte3 ist ein Zaehler). Byte0 Bit5 (0x20) = SET/- : 60 von 60 Tempomat-Starts heute, dazu Neusetzen der Sollgeschwindigkeit im laufenden Tempomat. Byte0 Bit0 (0x01) = CANCEL: 26 der 60 Tempomat-Enden heute, 149 -> 141 exakt zeitgleich. Byte0 Bit3 (0x08) = RES/+ : Soll steigt je Druck um 1 km/h (45 -> 46 -> 48 -> 49). Zusammen mit dem Bremsschalter (17 Enden) und der Kupplung (17 Enden, Kupplungsweg > 20 raw) erklaert das alle 60 Enden. Byte1 Bit5 siehe CruiseMainSwitch_maybe. Der Wert dieses Signals ist byte0*4 + Byte1-Top2Bit (SET=128, CANCEL=4, RES=32). 0x165 CC_Mode_Related nimmt beim Bremsen/Abbrechen die Werte 182/302/310 an, bei CANCEL direkt 141.";
CM_ SG_ 157 CruiseMainSwitch_maybe "Eigene Ergaenzung 2026-09-26, nur 5 Ereignisse: Byte1 Bit5 pulst 0,13 s beim ersten Tempomat-Hauptschalterdruck nach Zuendung EIN (CC_Mode_Related 129 -> 141, viermal in den ersten 10 s eines Logs, einmal bei 82 km/h zusammen mit Byte1 Bit6). Deutung: Hauptschalter EIN/AUS des Tempomats; 129 = Hauptschalter aus, 141 = ein/bereit.";
CM_ SG_ 304 iStop_StopRequest "Eigene Reverse-Engineering-Ergaenzung (2026-09-26). Byte3 Bit6 von 0x130: gesetzt waehrend jedes i-stop-Motorstopps (P=0,990 ueber 97 Stopps, 0,003 bei laufendem Motor) und zwar bereits 0,85 s BEVOR die Drehzahl faellt - Stoppanforderung. Gleiches Verhalten: iStop_StopRequest_PCM (0x167 Bit22). iStop_Stopping_A/B (Bit0/Bit10) setzen 0,58 s vor dem Drehzahlabfall; iStop_EngineStopped (Bit19) und iStop_EngineStopped_2 (0x050 Bit20) ab 0,85 s danach, solange der Motor automatisch steht (P=0,970).";
CM_ SG_ 304 iStop_Ready_maybe "Eigene Ergaenzung (2026-09-26). Byte2 Bit4 von 0x130: in der Warmlaufphase nach Kaltstart 0 (z.B. erste 79-377 s), danach meist 1 (84,5 % der Motorlaufzeit), vor JEDEM der 97 i-stop-Stopps gesetzt (P=1,000), nach Neustarts kurz wieder 0. Vermutlich 'i-stop-Bedingungen erfuellt' (gruene i-stop-Leuchte im Kombiinstrument). Fahrzeugtest: Leuchte gegen Bit beobachten.";
CM_ SG_ 578 LaneCurvature_maybe "Eigene Reverse-Engineering-Ergaenzung (2026-09-26), Bitlage aus opendbc mazda_2017 CAM_LANETRACK.LANE_CURVE (Offset -127), dort ohne Einheit. Gegen die tatsaechliche Bahnkruemmung Gierrate/v bei v > 60 km/h: r=0,94-0,97 in 4 von 4 Logs, bestes r bei 0,4-0,8 s Verzoegerung des Kamerawerts; gepoolt ueber 6 Logs (n=54.659): Kruemmung = 0,296 1/km je Schritt (hier 0,3 gerundet), Offset -0,18 1/km. Vorzeichen wie YawRate_Raw (SAE, + = links). Nur gueltig, wenn die Kamera eine Spur erkennt. Aufloesung ~3,4 km Radius je Schritt, also fuer Landstrassen-/Autobahnkurven, nicht fuer enge Kurven.";
CM_ SG_ 863 TSR_SpeedLimit "Eigene Reverse-Engineering-Ergaenzung (2026-09-26), Bitlage aus opendbc CAM_TRAFFIC_SIGNS.SPEED_SIGN. Von der Frontkamera erkanntes Tempolimit direkt in km/h: Werte 30/40/50/60/70/80/90/100/120 in bis zu 28 Logs, die gefahrene Geschwindigkeit passt dazu (90-%-Quantil z.B. 47 km/h bei 30, 63 bei 50, 133 bei 100, 153 bei 120). 0 = kein Limit erkannt bzw. aufgehoben (Autobahn, 90-%-Quantil 146 km/h). 5 und 10 kommen bei Schrittgeschwindigkeit vor (Bedeutung offen). Werte ueber 127 (130 km/h) passen nicht in 7 Bit - pruefen, ob dann ein anderer Code kommt.";
CM_ SG_ 578 LaneOffset_Line1_maybe "Eigene Reverse-Engineering-Ergaenzung (2026-09-26), Bitlage aus opendbc CAM_LANETRACK.LINE1 (Offset -686). Seitlicher Versatz des Fahrzeugs in der Spur, von der Frontkamera ueber die Linienlage geschaetzt: bei jedem Spurwechsel (Blinker, > 60 km/h) laeuft der Wert gleichmaessig weg und springt beim Ueberfahren der Linie um eine Spurbreite zurueck (Saegezahn), nach links negativ, nach rechts positiv. 233 solche Spruenge in allen Logs: Median 335 Schritte (IQR 310-362). 1 cm/LSB angenommen (ergibt 3,35 m Spurbreite, typisch Landstrasse/Autobahn); 3,5-3,75 m waeren 1,04-1,12 cm/LSB. LaneOffset_Line2_maybe (9|10) verlaeuft gespiegelt (zweite Schaetzung ueber die andere Linie, Sprung ebenfalls 334). Fahrzeugtest: auf gerader Strasse mit bekannter Spurbreite bewusst an linke/rechte Linie fahren. 2026-09-26: Test gefahren (B96, candump-2026-09-26_120235, 12:18-12:22). Ausschlaege von +71..+81 / -71..-97 in 3,5 min (sonst nirgends heute bei > 100 km/h), passend zu einem Rad auf der Linie (halbe Spurbreite 1,68 m - halbe Fahrzeugbreite 0,87 m = 0,80 m, also +-80 bei 1 cm/LSB). Scharfe Spitzen bis -175/+233: vier von sechs fallen mit Gasgeben/Bremsen zusammen (Nickartefakt vermutet), zwei ohne erkennbaren Ausloeser; keine Linienberuehrung (Rueckkehr in Zehntelsekunden).";
CM_ SG_ 581 CAM581_Curvature2_raw_maybe "Eigene Ergaenzung (2026-09-26). 0x245 Byte4 korreliert bei v > 60 km/h mit LaneCurvature_maybe (0x242) r=0,88 (0,63-0,91, 4 Logs) - zweite Kruemmungsgroesse des Spurmodells (andere Linie, Vorausschau oder Kruemmungsaenderung). Rohwert, Skala offen.";
CM_ SG_ 581 CAM581_LineDiff_raw_maybe "Eigene Ergaenzung (2026-09-26). 0x245 Byte0 korreliert mit LaneOffset_Line1-LaneOffset_Line2 (0x242) r=-0,88 (-0,85 bis -0,94, 4 Logs); die untere Nibble von Byte1 mit deren Summe (r=0,72). Vermutlich Spurbreite bzw. Lage der Spurmitte. Rohwert, Skala offen.";
CM_ SG_ 522 PCM_20A_Ramp_raw_maybe "Eigene Ergaenzung (2026-09-26). Byte0 Bit1..0 + Byte1 Bit7..2 (Byte1 Bit1..0 konstant 1) bilden EIN 8-Bit-Feld - die '117/118-Wechsel' in EngineState_raw_maybe waren dessen oberste Bits. Verhalten: steigt stufenweise bei Volllast UND im Schub (z.B. 126 -> 158 in 5 s), faellt langsam bei Teillast; keine Korrelation mit den ~80 Ankern (bestes |r| 0,40 gegen KnockRetard). Deutung offen (Adaption/Integrator?). EngineState_raw_maybe deshalb auf 6 Bit (7|6) verkuerzt: Werte = alter Rohwert >> 2 (117/118 -> 29, 53 -> 13, 86 -> 21, 245/246 -> 61).";
CM_ SG_ 512 PCM_TorqueLoss_raw_maybe "Eigene Ergaenzung (2026-09-26). Byte2-3, gleiche Kodierung wie Byte4-5 (raw-32768, um 0 zentriert). Werte meist -40..+10, Mittel -19..-26 bei warmem Motor; in der i-ELOOP-Rekuperation (DCDC_State_maybe=4) staerker negativ (-30..-36 gegen -19..-26, 3 Logs), bei kaltem Motor (< 60 Grad) in 2 von 3 Logs -40..-49. Keine Korrelation mit Pedal/Moment/Drehzahl-Aenderungen (|r| <= 0,3). Hypothese: Verlust-/Zusatzlastmoment (Reibung + Nebenaggregate, negativ = Last) in derselben Einheit wie Byte4-5 und TCS_TorqueRequest_maybe. Fahrzeugtest: im Leerlauf Klima und Heckscheibenheizung schalten - eine Lastmoment-Groesse muss sprunghaft negativer werden.";
CM_ SG_ 1180 RoadIncline_maybe "Eigene Reverse-Engineering-Ergaenzung (2026-09-26), scripts/can_field_inspect.py gegen den abgeleiteten Anker 'slope' (Laengsbeschleunigung minus Ableitung der Geschwindigkeit, 5-s-geglaettet). 0x49C (HS_IC) Byte7 Bit7..1 (Bit0 konstant 1), Rohwert/2 um 32 zentriert: gegen die Fahrbahnsteigung r=0,82-0,96 in 16 von 19 Logs (> 20 km/h, bestes r meist 1 s nach dem Kanal), gepoolt r=0,875 (n=232.412). Median der Referenz je Stufe: +-1 -> +-0,6..0,7 %, +-2 -> +-1,6 %, +-3 -> +-2,7..2,9 %, +-4 -> +-3,8 %, +-5 -> +-4,4..4,6 % - also ~1 % Steigung je Stufe (Regression 0,82, durch die Glaettung der Referenz eher unterschaetzt). Positiv = bergauf. Beobachtet -17..+12. Vermutlich die Neigungsschaetzung fuer die Berganfahrhilfe. Fahrzeugtest: auf einer Strasse mit bekannter Steigung (Schild) stehen bzw. langsam fahren.";
CM_ SG_ 529 ABS_Active "Eigene Reverse-Engineering-Ergaenzung (2026-09-15), scripts/can_event_bit_diff.py - der seit Wochen gesuchte ABS-EINGRIFFSINDIKATOR. Botschaft 0x211 (HS_ABS, 50 Hz) war bis dahin komplett leer. Gefunden in der Heimfahrt vom 15.09., dem ersten Log mit echten Regeleingriffen (bis 1,0 g quer, -0,98 g laengs, 194 km/h). BEFUND: das Bit ist ueber das gesamte 35-Minuten-Log zu 0,05% gesetzt, und zwar in genau ZWEI zusammenhaengenden Phasen - 1888,05-1888,45 s (0,40 s) und 1961,97-1962,63 s (0,66 s). Genau dort und nur dort zeigen die Radgeschwindigkeiten ABS-Modulation: bei der ersten Bremsung faellt Rad 2 (vorn rechts) zweimal um bis zu 9 km/h unter die drei anderen ab und springt jeweils wieder darueber zurueck (Druckabbau/Wiederaufbau, ~3 Hz), bei der zweiten dasselbe an Rad 1. Das Bit schaltet bei t=1888,052 ein, exakt als die Radspreizung erstmals ueber 4 km/h geht, bleibt waehrend der kurzen Erholung zwischen den Regelzyklen gesetzt (der Regler ist noch aktiv, Spreizung zwischenzeitlich nur 0,37 km/h) und faellt ab, sobald sich die Raeder gefangen haben. NEGATIVKONTROLLE: in der Hinfahrt desselben Tages (114.635 Frames von 0x211, 39 Minuten) ist das Bit zu 0,000% gesetzt - dort lag die maximale Radspreizung beim Bremsen auch nur bei 2,18 km/h. Ebenso 0,000% in candump-2026-09-11_180456. Es feuert auch nicht bei den Standbrems-Tests mit 72 bar und nicht bei hoher Querbeschleunigung. METHODIK: gefunden durch Vergleich der Bit-Setzquote WAEHREND der Regelphasen gegen den Rest DERSELBEN Bremsungen (Lift 0,88; innen 93%, in den Vergleichsphasen <5%). Ein Vergleich gegen den ganzen Rest des Logs funktioniert hier nicht - der findet nur Bremslichtschalter und Rueckschaltvorgaenge. OFFEN: ob dasselbe Bit auch bei einem reinen DSC-/Traktionseingriff ohne Bremsung gesetzt wird, ist mangels eines solchen Ereignisses im Datenbestand nicht geprueft.";
CM_ SG_ 529 TCS_Active_maybe "Eigene Reverse-Engineering-Ergaenzung (2026-09-26), scripts/can_rare_bits.py (Katalog seltener Bits ueber alle Logs). Byte5 Bit0. In 28 Logs nur 6 Episoden in 5 Logs (0,04-0,78 s), und JEDE liegt am Kurvenausgang beim Beschleunigen: Pedal 36-50 %, kein Bremsdruck, Querbeschleunigung 0,45-0,8 g, Hinterraeder 0,6-4,4 km/h schneller als die Vorderraeder, Gang 2-3. In den zwei laengsten Episoden (candump-2026-09-16_083214 t=45,4 s und 2026-09-16_081915 t=278,7 s) faellt ActualEnginePercentTorque bei konstantem Pedal deutlich ab (67 auf 7 % bzw. 64 auf 37 %), waehrend die Hinterachse bis 11,8 km/h durchdreht - die Signatur eines Motormoment-Eingriffs der Traktionskontrolle/DSC. Auch die am 2026-09-15 als 'kein Eingriff' verworfene Stelle (candump-2026-09-15_171047 t=726,2 s) traegt das Bit 0,26 s lang; der damalige Rarity-Scan verlangte >=80 % Setzquote im 37-s-Fenster und konnte es deshalb nicht sehen. ABS_Active ist dabei nie gesetzt - ein reiner Traktionseingriff setzt also ein EIGENES Bit. Gerade-aus-Schlupf bis 14 km/h ohne Querbeschleunigung setzt es NICHT (mehrere Faelle), das Bit reagiert eher auf Stabilitaet (Schlupf + Querdynamik) als auf reinen Schlupf. Unbestaetigt gegen die DSC-Kontrollleuchte (Fahrzeugtest: Warnleuchte beobachten).";
CM_ SG_ 529 HighDecel_maybe "Eigene Reverse-Engineering-Ergaenzung (2026-09-26), scripts/can_rare_bits.py. Byte5 Bit3: starke Verzoegerung. Ueber 775 Bremsungen in allen Logs in 13 gesetzt, und genau in denen mit Verzoegerung >= ~0,55-0,6 g (Setzquote je 50-Hz-Sample: 96 % bei -0,68 bis -0,85 g, 31 % bei -0,5 bis -0,59 g, 2 % bei -0,32 bis -0,41 g), unabhaengig von der Geschwindigkeit (26-224 km/h) und nicht vom Bremsdruck an sich (73 bar im Stand: nie gesetzt). Setzt 0,14-3,9 s nach Bremsbeginn ein, sobald die Schwelle erreicht ist. In allen drei ABS-Eingriffen ebenfalls gesetzt, ausserdem in allen drei Notbremssignal-Ereignissen (Warnblinker ohne Schalter, 0x09A Turn=3 bei HAZ_SW=0, candump-2026-09-15_171047). Vermutlich die Notbrems-/Bremsassistent-Erkennung des ABS-Steuergeraets. Unbestaetigt, welche Funktion es ausloest (Fahrzeugtest: Vollbremsung >0,6 g bei 60 km/h, Warnblinker beobachten). FAHRZEUGTEST C7 2026-09-26 (candump-2026-09-26_120235, zwei Vollbremsungen 12:16:05 und 12:16:16 aus 73 km/h, -0,87/-0,91 g, beide mit ABS): gesetzt 810,84-811,76 s und 821,92-822,28 s, Einschalten bei ~-0,74 bis -0,79 g; bei einer normalen Bremsung (-0,55 g, 14:19:31) nicht gesetzt. NACHTRAG 2026-09-26 (alle Logs, 16 Episoden in 6 Logs): Verzoegerung beim Einschalten (Longi_Acc_Corr) 0,46-0,84 g, Median 0,60 g; die hoeheren Werte (0,73-0,84 g, u.a. die beiden Vollbremsungen vom 26.09.) gehoeren zu steilen Bremsanstiegen, bei denen das Flag der Verzoegerung hinterherlaeuft. Einschaltschwelle damit ~0,55-0,6 g, unabhaengig von v (17-211 km/h). Direkt beim Abfallen (822,28 s) startete das Notbremssignal (Warnblinker schnell, siehe 154 EmergencyStopSignal_maybe) - bei der ersten Bremsung (Ende bei 24 km/h) nicht.";
CM_ SG_ 158 Fuel_Tank "LITER-KENNLINIE 2026-09-26 (Tank 16.09.->26.09., 66 Stuetzpunkte, verbrauchte Liter aus Bordcomputer*1,04): roh = 38,08 - 0,908*verbraucht_l (Rest 0,5 roh); mit voll = 45 l (Mazda-Angabe; aus 33 km Restreichweite + 9 l Reserve waeren es ~46 l, Abweichung ~1 l im Rahmen der Reichweiten-Schaetzung): Liter = 3,0 + 1,10*roh. Saettigt bei roh 36,2 (erste ~2,3 l nach dem Volltanken unsichtbar). Anzeige 0 (roh ~4,6) entspricht damit ~8 l. Bisherige Formel FLI% = 2,486*roh hat dieselbe Steigung (1,12 l/roh bei 45 l), aber keinen Sockel.";
CM_ SG_ 1267 AvgFuelConsumption "Eigene Reverse-Engineering-Ergaenzung (2026-09-26 abends, Fahrzeugtest C3): Byte4-5 big-endian = Durchschnittsverbrauch des Bordcomputers in 0,01 l/100km, Aktualisierung alle 60 s. Nach dem Zuruecksetzen (Nutzer setzte beim Tanken den Tageskilometerzaehler zurueck, der Durchschnittsverbrauch haengt daran) kommt 0xFFFE (=655,34, ungueltig) und der Mittelwert startet neu: 40,38 -> 19,38 -> 9,27 ... -> 6,31 l/100km (candump-2026-09-26_142216 ab 61,7 s = 14:23:17). Verlauf deckt sich mit Kraftstoffzaehler (0x420 Byte2) / Wegzaehler (0x420 Byte1) auf 2,6 ml genau, siehe FuelConsumption_Counter. Vorher ueber Wochen 7,2-8,5 l/100km; ein weiterer Reset in candump-2026-09-16_083214. Der Trip-Kilometerstand selbst wurde auf dem HS-CAN NICHT gefunden (Suche ueber alle Felder aller Botschaften negativ). Absolut: zeigt ~4,0 % zu wenig (Voll-bis-Voll 16.09.->26.09., siehe FuelConsumption_Counter).";
CM_ SG_ 832 DriverSeatbelt_Buckled "Eigene Reverse-Engineering-Ergaenzung (2026-09-26 abends): Byte3 Bit3 = Fahrer-Gurtschloss (Bitlage wie opendbc DRIVER_SEATBELT). Belege: candump-2026-09-26_120235 Einstecken 526,76 s (12:11:21), 2 s vor dem Schliessen der Fahrertuer - exakt die vom Nutzer genannte Reihenfolge; candump-2026-09-26_142216 ein 51,67 s, aus 120,23 s, Fahrertuer auf 123,24 / zu 133,96 s, wieder ein 138,55 s. Direkt nach Zuendung EIN fuer ~80 ms Initwert 1 (wie Bit26).";
CM_ SG_ 832 PassengerSeatEmpty_maybe "Eigene Reverse-Engineering-Ergaenzung (2026-09-26 abends): Byte3 High-Nibble ist der Belegungscode des Beifahrersitzes: 0xB = leer (Bit28=1), 0x6 = besetzt, Klassifizierung laeuft (Bit30=1), 0x2 = besetzt und bestaetigt (dann auch Bit16=1); 0x0/0x3 nur in den ersten Sekunden nach Zuendung. candump-2026-09-26_120235: Beifahrertuer auf 529,69 s, zu 537,73 s, Code B->6 bei 538,50 s (Sitz belegt), Gurt 545,09 s, Code 6->2 und Bit16 0->1 genau 60,0 s spaeter (598,51 s). Damit ist der bisher nie gesehene Zustand besetzt+nicht angeschnallt belegt (7 s) und die 60-s-Verzoegerung von Bit16 bezieht sich auf die Sitzbelegung, nicht auf den Motorstart. NACHTRAG 2026-09-26 (alle 42 Logs mit 0x340): Bit28 = leer ist in allen Logs konsistent (Codes 0x1/0x3/0x9/0xB leer, 0x2/0x6 besetzt), 7 Ein-/Ausstiege passen zu den Tuerereignissen (u.a. 093544 B->6 5,1 s / 2->B 763,7 s, 170350 B->6 122,6 s). Siehe PassengerSeatPending_maybe fuer Bit29-31.";
CM_ SG_ 832 PassengerSeatPending_maybe "Siehe PassengerSeatEmpty_maybe: Bit30 = Sitz besetzt, Insassenklassifizierung laeuft (60 s), danach Bit16. candump-2026-09-26_142216: Code 6 von 9,53 s bis 69,53 s nach Zuendung (Beifahrer sass bereits). NACHTRAG 2026-09-26 (alle 42 Logs mit 0x340): der Wechsel 6->2 kommt in allen 14 Faellen mit vollstaendigem Verlauf exakt 60,0 s nach 2->6 bzw. B->6. Bit30 = Klassifizierung laeuft (60 s ab Belegung), danach Bit16 = besetzt bestaetigt; Bit31 = leer bestaetigt (Codes 0x9/0xB, 5 s nach Zuendung). KEINE Kontrollleuchten: der Nutzer sah am 26.09. die Beifahrer-Leuchte beim Hinsetzen an- und beim Anschnallen ausgehen (7 s, nicht 60 s), und kein Bit auf dem HS-CAN folgt diesem Fenster (Suche 120235 538,5-545,1 s und 170350 122,6-130,3 s, nur das Gurtbit 26 selbst). Die Leuchte bildet das Kombiinstrument aus besetzt (Bit28=0) und Gurt offen (Bit26=0). Nach Zuendung EIN laeuft je Log dieselbe Initfolge 0x0 (3 s) -> 0x1/0x2/0x3 mit Bit16=1 fuer 2 s (Lampentest) -> Endzustand. Bit29 ist bei besetztem Sitz immer 1, bei leerem Sitz = Gurt offen (0xB) bzw. 0 bei gestecktem Gurt ohne Insasse (0x9, Solofahrten mit gestecktem Beifahrergurt).";
CM_ SG_ 154 EmergencyStopSignal_maybe "Eigene Reverse-Engineering-Ergaenzung (2026-09-26 abends, Fahrzeugtest C7): Byte7 Bit5 gesetzt waehrend das Notbremssignal die Warnblinker schnell blinken laesst (Turn=3 im 0,3-s-Takt statt normal ~0,7 s, HAZ_SW=0). candump-2026-09-26_120235: 822,28-824,93 s, Beginn exakt beim Abfallen von HighDecel_maybe nach der zweiten Vollbremsung (73->2 km/h, -0,91 g, ABS). Erst ein Ereignis, daher _maybe. NACHTRAG 2026-09-26 (alle Logs): 4 Episoden insgesamt (candump-2026-09-15_171047 1881,9/1888,0/1963,5 s und die obige), jede startet im selben Frame wie das Schnellblinken (Turn=3 bei HAZ_SW=0) und endet mit ihm; beim manuellen Warnblinker (Test candump-2026-09-12_120952) nie gesetzt. Damit als Flag bestaetigt, Name aus Kompatibilitaet behalten. Ausloesebedingung offen: allen 4 ging HighDecel_maybe voraus (3 mit ABS, 1 ohne bei -0,86 g), aber 11 andere HighDecel-Episoden (17-211 km/h, bis -0,95 g) loesten keins aus, darunter die erste Vollbremsung vom 26.09. (-0,95 g, ABS, Ende bei 24 km/h).";
CM_ SG_ 529 TCS_TorqueRequest_maybe "Eigene Reverse-Engineering-Ergaenzung (2026-09-26). Byte2-3 big-endian. Im Normalbetrieb konstant 0xFFFE (0xFFFF in den ersten ~20 Frames nach Zuendung), also 'keine Begrenzung'. In genau den Traktionseingriffen (gleiche Zeitfenster wie TCS_RequestActive_maybe und DSC_Indicator_maybe, 423 Frames in 8 Logs) nimmt es Werte um 0x8000 an (raw-32768 = -98 bis 632) und folgt dem Motormoment: in candump-2026-09-16_083214 t=45,5-46,2 s faellt es von 243 auf 0, waehrend ActualEnginePercentTorque bei konstantem Pedal von 67 auf 7 % sinkt; in candump-2026-09-18_093544 t=571,9-574,7 s (Vollgas, 1. Gang, Hinterachse 4-7 km/h schneller) liegt es bei 483-622 und das Moment bleibt bei 64-76 % statt Volllast. Korrelation mit ActualEnginePercentTorque r=0,77 (0,1 s spaeter), mit 0x200 Byte4-5 (raw-32768, gleiche Kodierung) r=0,84 ohne Versatz. Deutung: die von der Traktionskontrolle beim Motorsteuergeraet angeforderte Momenten-Obergrenze. Einheit NICHT kalibriert (Fit: %-Moment ~ 0,09*x+18; waere 0,25 Nm/LSB bei 205 Nm Maximalmoment plausibel). Kalibrierung braucht ein Nm-Referenzmoment waehrend eines Eingriffs.";
CM_ SG_ 529 TCS_RequestActive_maybe "Eigene Reverse-Engineering-Ergaenzung (2026-09-26). Byte6 Bit5 (Byte6 wechselt von 0 auf 32), gesetzt genau solange TCS_TorqueRequest_maybe von 0xFFFE abweicht (8 Episoden in 7 Logs, 0,06-2,9 s). Flag 'Momentenanforderung aktiv'.";
CM_ BO_ 977 "UNABHAENGIGE ZWEITBESTAETIGUNG von DistanceToService_related (2026-09-20, im Rahmen einer parallelen Suche nach dem Momentanverbrauch, urspruenglich unter dem Namen 'DistanceCountdown_maybe' als eigenes 16-Bit-Signal '47|16@0+ (0.25,0)' eingetragen - beim Zusammenfuehren mit der No-RTC-Uhr-Suche vom 2026-09-21 auf DistanceToService_related vereinheitlicht, siehe dortiger CM_-Kommentar fuer die crash-sichere 14-Bit-Variante): unabhaengig ueber einen VOELLIG ANDEREN Weg gefunden (Distanz-Sprung-Detektor statt Ganz-Log-Regression gegen C001_ODO) und trotzdem exakt dieselbe Bitlage (Byte5-6), Steigung (-4,000 Rohwert-Counts/km bzw. 0,25 km/Count - deckungsgleich mit raw14 = 173764-ODO_km) und Interpretation (Wartungsintervall-Restkilometer, nicht Verbrauch, da fahrverhaltensunabhaengig in allen geprueften Logs) ergeben - zwei unabhaengige Methoden, dieselbe Antwort. OFFENER PUNKT aus dieser Session, weiterhin unerledigt: Byte3-4 derselben Botschaft (16 Bit BE) zeigt eine unruhige, nicht-monotone Wertefolge (Vielfache von 32, Bereich ~0-2000) mit MODERATER aber INSTABILER Korrelation zu Drehzahl/nativem MAF-Proxy (can_bitsearch.py: R²=0,33-0,71 gegen RPM, Gewinner-Bitlage wandert zwischen Logs zwischen Byte3-Bit1 und Byte2-Bit0 - klassisches Zufallskorrelations-Muster wie bei den verworfenen AFR_MZ-Kandidaten) - nicht bestaetigungswuerdig, aber auffaellig genug fuer zukuenftige Momentanverbrauch-Sessions.";
CM_ BO_ 1087 "VIELVERSPRECHEND, NOCH NICHT BESTAETIGT (2026-09-15, externe Quelle github.com/gitgc/mx5-miata-nd2-obd-can): 0x43F 'Fuel_Related' (bisher nur als 10-Bit-Rohdefinition aus dem Original-Community-DBC, ungenutzt) - als VOLLE 16-Bit-Lesung (Byte0-1) interpretiert korreliert der Rohwert mit der OBD-Referenz FLI (0xF42F) in allen 3 geprueften Logs mit |r|=0.86-0.95, ABER das VORZEICHEN der Korrelation kippt zwischen den Logs (+0.95 im ersten, -0.86/-0.88 in den anderen zwei) - klassisches Warnsignal fuer eine ueber kurze Fahrten (Tankstand aendert sich pro Fahrt kaum) instabile, schwach besetzte Korrelation, nicht fuer ein falsches Signal an sich. Byte-Lage vermutlich richtig, Skala/Vorzeichen aber NICHT verlaesslich pro Log bestimmbar. Braucht Logs mit tatsaechlicher Tankstandsaenderung (z.B. vor/nach dem Tanken) zur sauberen Kalibrierung, bevor ein SG_ ergaenzt wird.";
CM_ BO_ 134 "GEPRUEFT, LINEARE FORMEL VERWORFEN (2026-09-15, externe Quelle github.com/gitgc/mx5-miata-nd2-obd-can): dort dokumentierte lineare Formel fuer Steering_Wheel_Absolute_Angle-aehnliches Feld (0x86, (16000-raw)*0.1) gegen unsere bestaetigte Referenz (Steering_Wheel_Absolute_Angle@0x82) getestet: Spearman r=-0.99 (starke monotone Uebereinstimmung, nur Vorzeichen gedreht), aber linearer Fit nur R²=0.25. Bestaetigt (statt widerlegt) unseren eigenen frueheren Befund, dass SteeringAngle_related@0x86 stark nichtlinear ist (siehe scripts/can_steering_angle_0x86.py, Isotonic-Regression) - die externe lineare Formel ist fuer unser Fahrzeug/diese Rohdaten nicht brauchbar, unser bestehendes Modell bleibt die richtige Loesung.";
CM_ SG_ 130 SteeringRate_Abs_maybe "NACHTRAG 2026-09-26: gegen den EPS-Diagnosewert STEER_SPD_EPS (UDS-DID 0x3301 an 0x730, 1 Byte, vom Handy im Y-Splitter-Log gepollt) in 4 Logs r=0,985-0,993, EPS_raw = 0,241-0,247 * dieser Kanal (Offset -1). Mit der ueblichen EPS-Aufloesung von 4 deg/s je Schritt ergaebe das 0,49 statt 0,5 deg/s je LSB - deckt sich mit der Steigung 0,468-0,486 gegen die Winkelableitung. Skala bleibt bei 0,5 (Abweichung ~2 %). Eigene Reverse-Engineering-Ergaenzung (2026-09-26), gefunden per Byte-Sweep-Neulauf (can_byte_search, Treffer 0x082 'b5-6' gegen STEER_SPD_EPS) und danach gegen die Ableitung des eigenen Lenkwinkels (Steering_Wheel_Absolute_Angle, gleiche Botschaft) geprueft: Betrag der Lenkwinkelgeschwindigkeit, 12 Bit little-endian = Byte6 (High) + Byte5 obere Nibble (Low; untere Nibble von Byte5 ist konstant 4). r(|d Winkel/dt|)=0,988-0,998 ueber ALLE 28 Logs >=20 MB, Steigung 0,468-0,486 deg/s je LSB, in jedem Log gleich (0,5 als runde Skala angenommen, Abweichung -3..-6% moeglicherweise durch Glaettung der Referenzableitung, nicht kalibriert). Vorzeichen in SteeringRate_Dir_maybe. Restoffset der Regression ca. -2 deg/s ungeklaert. Kein Bezug zu OBD-Kanal STEER_SPD_EPS noetig, der ist ein anderer Pfad (EPS-Modul 0x730).";
CM_ SG_ 130 SteeringRate_Dir_maybe "Eigene Reverse-Engineering-Ergaenzung (2026-09-26): Byte7 Bit0 = Vorzeichen zu SteeringRate_Abs_maybe. 1 = Lenkwinkel sinkt (Rate negativ), 0 = Winkel steigt. Korrelation mit sign(d Winkel/dt) bei |Rate|>20 deg/s: -0,9987 bzw. -0,9995 in zwei Logs.";
CM_ SG_ 1243 DCDC_State_maybe "Eigene Reverse-Engineering-Ergaenzung (2026-09-26), i-ELOOP/DCDC-Wandler (HS_DCDC, 10 Hz), aus dem Sweep-Neulauf (0x4DB gegen Soll-Lambda in 16 Logs) und danach gegen Gaspedal/Laengsbeschleunigung geprueft. Byte3 = 4: Rekuperation/Schubphase - in 5 Logs zu 100% bei geschlossenem Gaspedal (APP<1) und zu 91-98% bei Verzoegerung (acc<-0,03 g), Anteil 7,7-12,4% aller Frames; in den uebrigen Frames ist das Pedal nur zu 39-55% zu. Byte3 = 8: Normalzustand (~85%). Byte3 = 11: selten (338-2390 Frames), immer zusammen mit Byte4=248, Bedeutung offen (vermutlich Start-/Sonderzustand). Deckt sich nur teilweise mit FuelCut (0x0FD). Deutung als i-ELOOP-Rekuperation ist Hypothese (Physik passt, kein Referenzkanal).";
CM_ SG_ 1243 DCDC_RegenFlag_maybe "Byte0 Bit4, in der Rekuperation (State=4) immer 1, sonst 0. Eigene Ergaenzung 2026-09-26, siehe DCDC_State_maybe.";
CM_ SG_ 1243 DCDC_RegenLevel_maybe "Byte0 Bits 7-5, in der Rekuperation Stufen 0-4 (Rohwerte 22/54/86/118/150 bzw. 17/50/82/115/148 je nach Log, untere Nibble variiert). Faellt im Lauf einer Verzoegerung meist stufenweise ab (z.B. 86->54->22). Bedeutung unklar (Ladestrom-/Ladeleistungsstufe oder Kondensator-Ladezustand); Eigene Ergaenzung 2026-09-26.";
CM_ SG_ 522 EngineState_raw_maybe "Eigene Reverse-Engineering-Ergaenzung (2026-09-26), aus dem Sweep-Neulauf (0x20A gegen Soll-Lambda, 22 Logs). Byte0 ist ein Motorzustands-Byte (rohe Werte). Aus zwei Logs mit Kaltstart bzw. Auto-Stopp: 17-54 (meist 53) = Zuendung an, Motor steht (Drehzahl 0-1); 86 = Anlassen (2 Frames, Kupplung durchgetreten); 117/118 = Motor laeuft (Leerlauf bzw. Fahrt, Bit0/1 wechseln zwischen 117 und 118, Bedeutung offen); 245/246 = Motor steht wieder nach dem Lauf (Drehzahl ~20, Kuehlwasser 90 Grad, nur im Log 09-14_081105, vermutlich i-stop-Automatikstopp). Nur aus 2 Logs gelesen, Zuordnung nicht referenzgestuetzt.";
CM_ SG_ 522 FuelNotCut_maybe "Eigene Reverse-Engineering-Ergaenzung (2026-09-26). Byte4 Bit7: 1 im Normalbetrieb, 0 in einer TEILMENGE der Schubabschaltung. Gegen Soll-Lambda > 1,9 (PID 0x44) in drei Logs: P(Bit=0 | Schub) = 0,81/0,85/0,83, P(Schub | Bit=0) = 0,95/0,96/0,77; nie 0 bei Gaspedal >= 1 (0,000), zu 18-23% bei Pedal zu. FuelCut (0x0FD Byte5 Bit1) deckt den Schub besser ab (P=0,98/0,98/0,91), dieses Bit liefert also nichts Neues, eher eine Untermenge (vermutlich 'stabile' Schubabschaltung nach Verzoegerungszeit). Damit ist auch der Sweep-Treffer 0x20A gegen Soll-Lambda (r 0,64-0,85 in 22 Logs) erklaert.";
CM_ SG_ 130 SteeringRate_Abs_maybe "ERSETZT (2026-09-26) das am 2026-09-20 eingetragene SteeringWheelSpeed_related (54|9@0+, 9 Bit, ohne Vorzeichen, gegen STEER_SPD_EPS bestaetigt). Beide sind dieselbe Groesse (r=0,995 bzw. 0,987 zwischen altem 9-Bit- und diesem 12-Bit-Betrag in zwei Logs, beide r=0,99 gegen |d Winkel/dt|), das neue Feld ist aber feiner aufgeloest (12 statt 9 Bit, Startbit 44 statt 48) und traegt mit SteeringRate_Dir_maybe das Vorzeichen; ein Ueberlapp haette beide Definitionen im DBC unmoeglich gemacht.";
CM_ SG_ 120 BrakePressure "NACHKALIBRIERT (2026-09-29, scripts/can_obd_scale_recheck.py): Skala 0.0012413 -> 0.0012709, Offset 32.7986 -> 33.5487 (+2,4 %). Die 12.09.-Kalibrierung hatte die ~2-Hz-Referenz linear auf ein 5-Hz-Raster interpoliert und gegen die .dlg-Zeitachse gepaart (daher Lag -0,3 s). Jetzt gegen die DID 0x280A direkt aus dem CAN-Log (BFP_PRE_MZ kPa = raw, exakt gegen die .dlg bestimmt), Kandidat an den Referenz-Zeitstempeln abgelesen: 4 Logs (12_211833, 14_081105, 14_163711, 14_173057), je Log 0.0012663-0.0012719, R2 0,999-1,000, Lag -0,02 s, gepoolt n=14053. Ruhelage raw -26429 -> -0,04 bar.";
CM_ SG_ 359 ActualEnginePercentTorque "NACHKALIBRIERT (2026-09-29, scripts/can_obd_scale_recheck.py): 3.0242*raw-177.849 -> 3.1028*raw-183.019 (+2,6 %). Die 15.09.-Kalibrierung (can_find_native_counterpart.py) hatte PID 0x62 linear auf ein 5-s-Raster interpoliert. Jetzt Kandidat an den PID-Zeitstempeln abgelesen, 25 Logs, gepoolt n=109490, R2 0,977, Lag 0-0,02 s. Streuung der Steigung je Fahrt 2,88-3,25 bleibt groesser als die Korrektur - Genauigkeit weiterhin ~4 Prozentpunkte.";
CM_ SG_ 1114 BattSensor_Voltage_maybe "NACHKALIBRIERT (2026-09-29, scripts/can_obd_scale_recheck.py): 1/512 V -> 0,002 V/LSB mit -0,1 V Offset. Gegen PID 0x42 (alle 10 s) an den PID-Zeitstempeln: 22 Logs, gepoolt 0,00200264*raw-0,1006 V, R2 0,997 (vorher r=0,966 mit interpolierter Referenz). Die runde Skala weicht bei 12,5 V um 0,016 V vom Fit ab. Weiter _maybe (Messpunkt/Bedeutung nicht per Multimeter bestaetigt).";
CM_ SG_ 304 Clutch_Pedal_Position_raw "NACHGERECHNET (2026-09-29, scripts/can_obd_scale_recheck.py): Pedalweg in % = raw/2 exakt (gegen CPP_PER_MZ DID 0x0478, % = raw*100/65535, 4 Logs, R2 1,000, Lag 0). Die fruehere Kalibrierung 0,4665*raw+0,56 (12.09.) war ein Interpolations-/Uhrenpaarungs-Artefakt. Bisspunkt raw 114-123 = 57-61,5 %. Signal bleibt als Rohwert (1,0) definiert.";
